AUTOSAR XML (schema 4-0-3)
package /MICROSAR/Dem_swc/DataTypes
  19 x impl type:
    Dem_EventIdType: range raw 1..65535, implementation-data-type=uint16
    Dem_RatioIdType: range raw 1..65535, implementation-data-type=uint16
    Dem_DTCStatusMaskType: range raw 0..255, implementation-data-type=uint8
    Dem_OperationCycleIdType: range raw 0..255, implementation-data-type=uint8
    Dem_DTCGroupType: range raw 0..16777215, implementation-data-type=uint32
    Dem_MaxDataValueType: category=ARRAY, sw-calibration-access=READ-ONLY
      element Dem_MaxDataValueTypeElement: array-size=1, array-size-semantics=FIXED-SIZE, implementation-data-type=uint8
    Dem_EventStatusType: compu {0=DEM_EVENT_STATUS_PASSED, 1=DEM_EVENT_STATUS_FAILED, 2=DEM_EVENT_STATUS_PREPASSED, 3=DEM_EVENT_STATUS_PREFAILED}, implementation-data-type=uint8
    Dem_EventStatusExtendedType: compu {1=DEM_UDS_STATUS_TF, 2=DEM_UDS_STATUS_TFTOC, 4=DEM_UDS_STATUS_PDTC, 8=DEM_UDS_STATUS_CDTC, 16=DEM_UDS_STATUS_TNCSLC, 32=DEM_UDS_STATUS_TFSLC, 64=DEM_UDS_STATUS_TNCTOC, 128=DEM_UDS_STATUS_WIR}, implementation-data-type=uint8
    Dem_InitMonitorReasonType: compu {1=DEM_INIT_MONITOR_CLEAR, 2=DEM_INIT_MONITOR_RESTART, 3=DEM_INIT_MONITOR_REENABLED}, implementation-data-type=uint8
    Dem_DTCOriginType: compu {1=DEM_DTC_ORIGIN_PRIMARY_MEMORY, 2=DEM_DTC_ORIGIN_MIRROR_MEMORY, 3=DEM_DTC_ORIGIN_PERMANENT_MEMORY, 4=DEM_DTC_ORIGIN_SECONDARY_MEMORY}, implementation-data-type=uint8
    Dem_DTCFormatType: compu {0=DEM_DTC_FORMAT_OBD, 1=DEM_DTC_FORMAT_UDS, 2=DEM_DTC_FORMAT_J1939}, implementation-data-type=uint8
    Dem_OperationCycleStateType: compu {0=DEM_CYCLE_STATE_START, 1=DEM_CYCLE_STATE_END}, implementation-data-type=uint8
    Dem_IndicatorStatusType: compu {0=DEM_INDICATOR_OFF, 1=DEM_INDICATOR_CONTINUOUS, 2=DEM_INDICATOR_BLINKING, 3=DEM_INDICATOR_BLINK_CONT, 4=DEM_INDICATOR_SLOW_FLASH, 5=DEM_INDICATOR_FAST_FLASH, 6=DEM_INDICATOR_ON_DEMAND, 7=DEM_INDICATOR_SHORT}, implementation-data-type=uint8
    Dem_DTCKindType: compu {1=DEM_DTC_KIND_ALL_DTCS, 2=DEM_DTC_KIND_EMISSION_REL_DTCS}, implementation-data-type=uint8
    Dem_IumprDenomCondIdType: compu {1=DEM_IUMPR_GENERAL_DENOMINATOR, 2=DEM_IUMPR_DEN_COND_COLDSTART, 3=DEM_IUMPR_DEN_COND_EVAP, 4=DEM_IUMPR_DEN_COND_500MI}, implementation-data-type=uint8
    Dem_IumprDenomCondStatusType: compu {0=DEM_IUMPR_DEN_STATUS_NOT_REACHED, 1=DEM_IUMPR_DEN_STATUS_REACHED, 2=DEM_IUMPR_DEN_STATUS_INHIBITED}, implementation-data-type=uint8
    Dem_DebounceResetStatusType: compu {0=DEM_DEBOUNCE_STATUS_FREEZE, 1=DEM_DEBOUNCE_STATUS_RESET}, implementation-data-type=uint8
    Dem_DebouncingStateType: compu {1=DEM_TEMPORARILY_DEFECTIVE, 2=DEM_FINALLY_DEFECTIVE, 4=DEM_TEMPORARILY_HEALED, 8=DEM_TEST_COMPLETE, 16=DEM_DTR_UPDATE}, implementation-data-type=uint8
    DataArray_Type_1: category=ARRAY, sw-calibration-access=READ-ONLY
      element DataArray_Type_1Element: array-size=1, array-size-semantics=FIXED-SIZE, implementation-data-type=uint8
package /MICROSAR/Dem_swc/Interfaces
  11 x client server interface, all with is-service=true, service-kind=DIAGNOSTIC-EVENT-MANAGER:
    CddIf
      operation ClearDTC: possible-error=[CddIf/DEM_CLEAR_WRONG_DTC, CddIf/DEM_CLEAR_WRONG_DTCORIGIN, CddIf/DEM_CLEAR_FAILED, CddIf/DEM_CLEAR_PENDING, CddIf/DEM_CLEAR_BUSY]
        arg DTC: type=uint32, direction=IN
        arg DTCFormat: type=Dem_DTCFormatType, direction=IN
        arg DTCOrigin: type=Dem_DTCOriginType, direction=IN
      5 x error:
        DEM_CLEAR_WRONG_DTC: error-code=1
        DEM_CLEAR_WRONG_DTCORIGIN: error-code=2
        DEM_CLEAR_FAILED: error-code=3
        DEM_CLEAR_PENDING: error-code=4
        DEM_CLEAR_BUSY: error-code=5
    DemServices
      operation GetPostRunRequested: possible-error=DemServices/E_NOT_OK
        arg IsRequested: type=boolean, direction=OUT
      operation GetDTCStatusAvailabilityMask: possible-error=DemServices/E_NOT_OK
        arg DTCStatusMask: type=uint8, direction=OUT
      error E_NOT_OK: error-code=1
    EvMemOverflowIndication
      operation GetEventMemoryOverflow: possible-error=EvMemOverflowIndication/E_NOT_OK
        arg OverflowIndication: type=boolean, direction=OUT
      operation GetNumberOfEventMemoryEntries: possible-error=EvMemOverflowIndication/E_NOT_OK
        arg NumberOfEventMemoryEntries: type=uint8, direction=OUT
      error E_NOT_OK: error-code=1
    GeneralDiagnosticInfo
      9 x operation:
        GetEventStatus: possible-error=GeneralDiagnosticInfo/E_NOT_OK
          arg EventId: type=Dem_EventIdType, direction=IN
          arg EventStatusExtended: type=Dem_EventStatusExtendedType, direction=OUT
        GetEventFailed: possible-error=GeneralDiagnosticInfo/E_NOT_OK
          arg EventId: type=Dem_EventIdType, direction=IN
          arg EventFailed: type=boolean, direction=OUT
        GetEventTested: possible-error=GeneralDiagnosticInfo/E_NOT_OK
          arg EventId: type=Dem_EventIdType, direction=IN
          arg EventTested: type=boolean, direction=OUT
        GetDTCOfEvent: possible-error=[GeneralDiagnosticInfo/E_NOT_OK, GeneralDiagnosticInfo/DEM_E_NO_DTC_AVAILABLE]
          arg EventId: type=Dem_EventIdType, direction=IN
          arg DTCFormat: type=Dem_DTCFormatType, direction=IN
          arg DTCOfEvent: type=uint32, direction=OUT
        GetFaultDetectionCounter: possible-error=[GeneralDiagnosticInfo/E_NOT_OK, GeneralDiagnosticInfo/DEM_E_NO_FDC_AVAILABLE]
          arg EventId: type=Dem_EventIdType, direction=IN
          arg FaultDetectionCounter: type=sint8, direction=OUT
        GetEventFreezeFrameData: possible-error=[GeneralDiagnosticInfo/E_NOT_OK, GeneralDiagnosticInfo/DEM_E_NODATAAVAILABLE, GeneralDiagnosticInfo/DEM_E_WRONG_RECORDNUMBER, GeneralDiagnosticInfo/DEM_E_WRONG_DIDNUMBER]
          5 x arg:
            EventId: type=Dem_EventIdType, direction=IN
            RecordNumber: type=uint8, direction=IN
            ReportTotalRecord: type=boolean, direction=IN
            DataId: type=uint16, direction=IN
            DestBuffer: type=Dem_MaxDataValueType, direction=OUT
        GetEventExtendedDataRecord: possible-error=[GeneralDiagnosticInfo/E_NOT_OK, GeneralDiagnosticInfo/DEM_E_NODATAAVAILABLE, GeneralDiagnosticInfo/DEM_E_WRONG_RECORDNUMBER]
          arg EventId: type=Dem_EventIdType, direction=IN
          arg RecordNumber: type=uint8, direction=IN
          arg DestBuffer: type=Dem_MaxDataValueType, direction=OUT
        GetEventEnableCondition: possible-error=GeneralDiagnosticInfo/E_NOT_OK
          arg EventId: type=Dem_EventIdType, direction=IN
          arg ConditionFullfilled: type=boolean, direction=OUT
        GetDebouncingOfEvent: possible-error=GeneralDiagnosticInfo/E_NOT_OK
          arg EventId: type=Dem_EventIdType, direction=IN
          arg DebouncingState: type=Dem_DebouncingStateType, direction=OUT
      6 x error:
        E_NOT_OK: error-code=1
        DEM_E_NO_DTC_AVAILABLE: error-code=2
        DEM_E_NO_FDC_AVAILABLE: error-code=3
        DEM_E_NODATAAVAILABLE: error-code=48
        DEM_E_WRONG_RECORDNUMBER: error-code=49
        DEM_E_WRONG_DIDNUMBER: error-code=50
    DiagnosticInfo
      9 x operation:
        GetEventStatus: possible-error=DiagnosticInfo/E_NOT_OK
          arg EventStatusExtended: type=Dem_EventStatusExtendedType, direction=OUT
        GetEventFailed: possible-error=DiagnosticInfo/E_NOT_OK
          arg EventFailed: type=boolean, direction=OUT
        GetEventTested: possible-error=DiagnosticInfo/E_NOT_OK
          arg EventTested: type=boolean, direction=OUT
        GetDTCOfEvent: possible-error=[DiagnosticInfo/E_NOT_OK, DiagnosticInfo/DEM_E_NO_DTC_AVAILABLE]
          arg DTCFormat: type=Dem_DTCFormatType, direction=IN
          arg DTCOfEvent: type=uint32, direction=OUT
        GetFaultDetectionCounter: possible-error=[DiagnosticInfo/E_NOT_OK, DiagnosticInfo/DEM_E_NO_FDC_AVAILABLE]
          arg FaultDetectionCounter: type=sint8, direction=OUT
        GetEventFreezeFrameData: possible-error=[DiagnosticInfo/E_NOT_OK, DiagnosticInfo/DEM_E_NODATAAVAILABLE, DiagnosticInfo/DEM_E_WRONG_RECORDNUMBER, DiagnosticInfo/DEM_E_WRONG_DIDNUMBER]
          4 x arg:
            RecordNumber: type=uint8, direction=IN
            ReportTotalRecord: type=boolean, direction=IN
            DataId: type=uint16, direction=IN
            DestBuffer: type=Dem_MaxDataValueType, direction=OUT
        GetEventExtendedDataRecord: possible-error=[DiagnosticInfo/E_NOT_OK, DiagnosticInfo/DEM_E_NODATAAVAILABLE, DiagnosticInfo/DEM_E_WRONG_RECORDNUMBER]
          arg RecordNumber: type=uint8, direction=IN
          arg DestBuffer: type=Dem_MaxDataValueType, direction=OUT
        GetEventEnableCondition: possible-error=DiagnosticInfo/E_NOT_OK
          arg ConditionFullfilled: type=boolean, direction=OUT
        GetDebouncingOfEvent: possible-error=DiagnosticInfo/E_NOT_OK
          arg DebouncingState: type=Dem_DebouncingStateType, direction=OUT
      6 x error:
        E_NOT_OK: error-code=1
        DEM_E_NO_DTC_AVAILABLE: error-code=2
        DEM_E_NO_FDC_AVAILABLE: error-code=3
        DEM_E_NODATAAVAILABLE: error-code=48
        DEM_E_WRONG_RECORDNUMBER: error-code=49
        DEM_E_WRONG_DIDNUMBER: error-code=50
    DiagnosticMonitor
      10 x operation:
        SetEventStatus: possible-error=DiagnosticMonitor/E_NOT_OK
          arg EventStatus: type=Dem_EventStatusType, direction=IN
        ResetEventStatus: possible-error=DiagnosticMonitor/E_NOT_OK
        ResetEventDebounceStatus: possible-error=DiagnosticMonitor/E_NOT_OK
          arg DebounceResetStatus: type=Dem_DebounceResetStatusType, direction=IN
        GetEventStatus: possible-error=DiagnosticMonitor/E_NOT_OK
          arg EventStatusExtended: type=Dem_EventStatusExtendedType, direction=OUT
        GetEventFailed: possible-error=DiagnosticMonitor/E_NOT_OK
          arg EventFailed: type=boolean, direction=OUT
        GetEventTested: possible-error=DiagnosticMonitor/E_NOT_OK
          arg EventTested: type=boolean, direction=OUT
        GetDTCOfEvent: possible-error=[DiagnosticMonitor/E_NOT_OK, DiagnosticMonitor/DEM_E_NO_DTC_AVAILABLE]
          arg DTCFormat: type=Dem_DTCFormatType, direction=IN
          arg DTCOfEvent: type=uint32, direction=OUT
        GetFaultDetectionCounter: possible-error=[DiagnosticMonitor/E_NOT_OK, DiagnosticMonitor/DEM_E_NO_FDC_AVAILABLE]
          arg FaultDetectionCounter: type=sint8, direction=OUT
        GetEventFreezeFrameData: possible-error=[DiagnosticMonitor/E_NOT_OK, DiagnosticMonitor/DEM_E_NODATAAVAILABLE, DiagnosticMonitor/DEM_E_WRONG_RECORDNUMBER, DiagnosticMonitor/DEM_E_WRONG_DIDNUMBER]
          4 x arg:
            RecordNumber: type=uint8, direction=IN
            ReportTotalRecord: type=boolean, direction=IN
            DataId: type=uint16, direction=IN
            DestBuffer: type=Dem_MaxDataValueType, direction=OUT
        GetEventExtendedDataRecord: possible-error=[DiagnosticMonitor/E_NOT_OK, DiagnosticMonitor/DEM_E_NODATAAVAILABLE, DiagnosticMonitor/DEM_E_WRONG_RECORDNUMBER]
          arg RecordNumber: type=uint8, direction=IN
          arg DestBuffer: type=Dem_MaxDataValueType, direction=OUT
      6 x error:
        E_NOT_OK: error-code=1
        DEM_E_NO_DTC_AVAILABLE: error-code=2
        DEM_E_NO_FDC_AVAILABLE: error-code=3
        DEM_E_NODATAAVAILABLE: error-code=48
        DEM_E_WRONG_RECORDNUMBER: error-code=49
        DEM_E_WRONG_DIDNUMBER: error-code=50
    DcmIf
      5 x operation:
        DcmClearDTC: possible-error=[DcmIf/DEM_CLEAR_WRONG_DTC, DcmIf/DEM_CLEAR_WRONG_DTCORIGIN, DcmIf/DEM_CLEAR_FAILED, DcmIf/DEM_CLEAR_PENDING, DcmIf/DEM_CLEAR_BUSY]
          arg DTC: type=uint32, direction=IN
          arg DTCFormat: type=Dem_DTCFormatType, direction=IN
          arg DTCOrigin: type=Dem_DTCOriginType, direction=IN
        DcmGetNextFilteredDTCAndFDC: possible-error=DEM_FILTERED_NO_MATCHING_DTC
          arg DTC: type=uint32, direction=OUT
          arg DTCFaultDetectionCounter: type=sint8, direction=OUT
        DcmEnableDTCSetting: possible-error=[DEM_CONTROL_DTC_SETTING_N_OK, DEM_CONTROL_DTC_WRONG_DTCGROUP]
          arg DTCGroup: type=Dem_DTCGroupType, direction=IN
          arg DTCKind: type=Dem_DTCKindType, direction=IN
        DcmGetFreezeFrameDataByDTC: possible-error=[DEM_GET_FFDATABYDTC_WRONG_DTC, DEM_GET_FFDATABYDTC_WRONG_DTCORIGIN, DEM_GET_FFDATABYDTC_WRONG_RECORDNUMBER, DEM_GET_FFDATABYDTC_WRONG_BUFFERSIZE, DEM_GET_FFDATABYDTC_PENDING]
          5 x arg:
            DTC: type=uint32, direction=IN
            DTCOrigin: type=Dem_DTCOriginType, direction=IN
            RecordNumber: type=uint8, direction=IN
            DestBuffer: type=uint8, direction=OUT
            BufSize: type=uint16, direction=INOUT
        DcmGetExtendedDataRecordByDTC: possible-error=[DEM_RECORD_WRONG_DTC, DEM_RECORD_WRONG_DTCORIGIN, DEM_RECORD_WRONG_NUMBER, DEM_RECORD_WRONG_BUFFERSIZE, DEM_RECORD_PENDING]
          5 x arg:
            DTC: type=uint32, direction=IN
            DTCOrigin: type=Dem_DTCOriginType, direction=IN
            ExtendedDataNumber: type=uint8, direction=IN
            DestBuffer: type=uint8, direction=OUT
            BufSize: type=uint16, direction=INOUT
      18 x error:
        DEM_CLEAR_WRONG_DTC: error-code=1
        DEM_CONTROL_DTC_SETTING_N_OK: error-code=1
        DEM_FILTERED_NO_MATCHING_DTC: error-code=1
        DEM_GET_FFDATABYDTC_WRONG_DTC: error-code=1
        DEM_RECORD_WRONG_DTC: error-code=1
        DEM_CLEAR_WRONG_DTCORIGIN: error-code=2
        DEM_CONTROL_DTC_WRONG_DTCGROUP: error-code=2
        DEM_GET_FFDATABYDTC_WRONG_DTCORIGIN: error-code=2
        DEM_RECORD_WRONG_DTCORIGIN: error-code=2
        DEM_CLEAR_FAILED: error-code=3
        DEM_GET_FFDATABYDTC_WRONG_RECORDNUMBER: error-code=3
        DEM_RECORD_WRONG_NUMBER: error-code=3
        DEM_CLEAR_PENDING: error-code=4
        DEM_GET_FFDATABYDTC_WRONG_BUFFERSIZE: error-code=4
        DEM_RECORD_WRONG_BUFFERSIZE: error-code=4
        DEM_CLEAR_BUSY: error-code=5
        DEM_GET_FFDATABYDTC_PENDING: error-code=5
        DEM_RECORD_PENDING: error-code=5
    OperationCycle
      operation SetOperationCycleState: possible-error=OperationCycle/E_NOT_OK
        arg CycleState: type=Dem_OperationCycleStateType, direction=IN
      error E_NOT_OK: error-code=1
    CSDataServices_DID_0_Unknown_1
      operation ReadData: possible-error=CSDataServices_DID_0_Unknown_1/E_NOT_OK
        arg Data: type=DataArray_Type_1, direction=OUT
      error E_NOT_OK: error-code=1
    CSDataServices_DID_0x1_Unknown_1
      operation ReadData: possible-error=CSDataServices_DID_0x1_Unknown_1/E_NOT_OK
        arg Data: type=DataArray_Type_1, direction=OUT
      error E_NOT_OK: error-code=1
    CSDataServices_ExtendedDataRecord1_Unknown_1
      operation ReadData: possible-error=CSDataServices_ExtendedDataRecord1_Unknown_1/E_NOT_OK
        arg Data: type=DataArray_Type_1, direction=OUT
      error E_NOT_OK: error-code=1
package /MICROSAR/Dem_swc/ComponentTypes
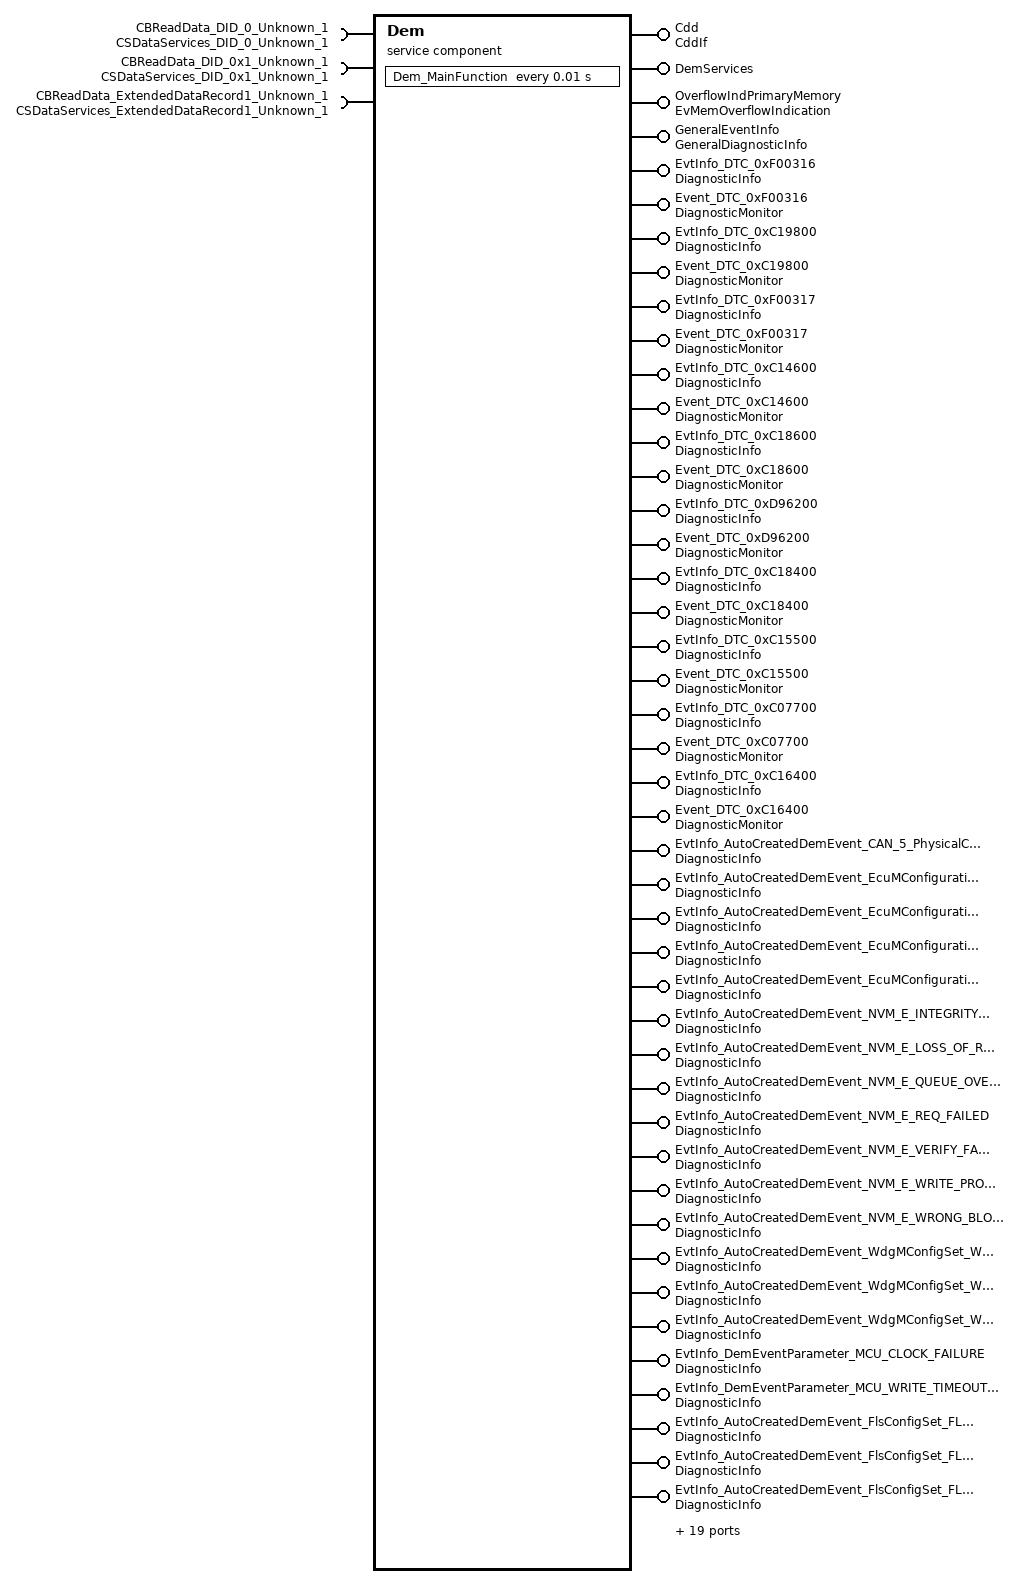
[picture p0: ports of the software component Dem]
  service sw component type Dem: category=SERVICE_COMPONENT
    63 x provide port:
      Cdd: provided-interface=CddIf
      DemServices: provided-interface=DemServices
      OverflowIndPrimaryMemory: provided-interface=EvMemOverflowIndication
      GeneralEventInfo: provided-interface=GeneralDiagnosticInfo
      EvtInfo_DTC_0xF00316: provided-interface=DiagnosticInfo
      Event_DTC_0xF00316: provided-interface=DiagnosticMonitor
      EvtInfo_DTC_0xC19800: provided-interface=DiagnosticInfo
      Event_DTC_0xC19800: provided-interface=DiagnosticMonitor
      EvtInfo_DTC_0xF00317: provided-interface=DiagnosticInfo
      Event_DTC_0xF00317: provided-interface=DiagnosticMonitor
      EvtInfo_DTC_0xC14600: provided-interface=DiagnosticInfo
      Event_DTC_0xC14600: provided-interface=DiagnosticMonitor
      EvtInfo_DTC_0xC18600: provided-interface=DiagnosticInfo
      Event_DTC_0xC18600: provided-interface=DiagnosticMonitor
      EvtInfo_DTC_0xD96200: provided-interface=DiagnosticInfo
      Event_DTC_0xD96200: provided-interface=DiagnosticMonitor
      EvtInfo_DTC_0xC18400: provided-interface=DiagnosticInfo
      Event_DTC_0xC18400: provided-interface=DiagnosticMonitor
      EvtInfo_DTC_0xC15500: provided-interface=DiagnosticInfo
      Event_DTC_0xC15500: provided-interface=DiagnosticMonitor
      EvtInfo_DTC_0xC07700: provided-interface=DiagnosticInfo
      Event_DTC_0xC07700: provided-interface=DiagnosticMonitor
      EvtInfo_DTC_0xC16400: provided-interface=DiagnosticInfo
      Event_DTC_0xC16400: provided-interface=DiagnosticMonitor
      EvtInfo_AutoCreatedDemEvent_CAN_5_PhysicalChannel_09246746_CANSM_E_BUS_OFF: provided-interface=DiagnosticInfo
      EvtInfo_AutoCreatedDemEvent_EcuMConfiguration_ECUM_E_ALL_RUN_REQUESTS_KILLED: provided-interface=DiagnosticInfo
      EvtInfo_AutoCreatedDemEvent_EcuMConfiguration_ECUM_E_CONFIGURATION_DATA_INCONSISTENT: provided-interface=DiagnosticInfo
      EvtInfo_AutoCreatedDemEvent_EcuMConfiguration_ECUM_E_RAM_CHECK_FAILED: provided-interface=DiagnosticInfo
      EvtInfo_AutoCreatedDemEvent_EcuMConfiguration_ECUM_E_IMPROPER_CALLER: provided-interface=DiagnosticInfo
      EvtInfo_AutoCreatedDemEvent_NVM_E_INTEGRITY_FAILED: provided-interface=DiagnosticInfo
      EvtInfo_AutoCreatedDemEvent_NVM_E_LOSS_OF_REDUNDANCY: provided-interface=DiagnosticInfo
      EvtInfo_AutoCreatedDemEvent_NVM_E_QUEUE_OVERFLOW: provided-interface=DiagnosticInfo
      EvtInfo_AutoCreatedDemEvent_NVM_E_REQ_FAILED: provided-interface=DiagnosticInfo
      EvtInfo_AutoCreatedDemEvent_NVM_E_VERIFY_FAILED: provided-interface=DiagnosticInfo
      EvtInfo_AutoCreatedDemEvent_NVM_E_WRITE_PROTECTED: provided-interface=DiagnosticInfo
      EvtInfo_AutoCreatedDemEvent_NVM_E_WRONG_BLOCK_ID: provided-interface=DiagnosticInfo
      EvtInfo_AutoCreatedDemEvent_WdgMConfigSet_WDGM_E_IMPROPER_CALLER: provided-interface=DiagnosticInfo
      EvtInfo_AutoCreatedDemEvent_WdgMConfigSet_WDGM_E_MONITORING: provided-interface=DiagnosticInfo
      EvtInfo_AutoCreatedDemEvent_WdgMConfigSet_WDGM_E_SET_MODE: provided-interface=DiagnosticInfo
      EvtInfo_DemEventParameter_MCU_CLOCK_FAILURE: provided-interface=DiagnosticInfo
      EvtInfo_DemEventParameter_MCU_WRITE_TIMEOUT_FAILURE: provided-interface=DiagnosticInfo
      EvtInfo_AutoCreatedDemEvent_FlsConfigSet_FLS_E_COMPARE_FAILED: provided-interface=DiagnosticInfo
      EvtInfo_AutoCreatedDemEvent_FlsConfigSet_FLS_E_ERASE_FAILED: provided-interface=DiagnosticInfo
      EvtInfo_AutoCreatedDemEvent_FlsConfigSet_FLS_E_READ_FAILED: provided-interface=DiagnosticInfo
      EvtInfo_AutoCreatedDemEvent_FlsConfigSet_FLS_E_UNEXPECTED_FLASH_ID: provided-interface=DiagnosticInfo
      EvtInfo_AutoCreatedDemEvent_FlsConfigSet_FLS_E_WRITE_FAILED: provided-interface=DiagnosticInfo
      EvtInfo_AutoCreatedDemEvent_WDG_E_DISABLE_REJECTED: provided-interface=DiagnosticInfo
      EvtInfo_AutoCreatedDemEvent_WDG_E_MODE_FAILED: provided-interface=DiagnosticInfo
      EvtInfo_AutoCreatedDemEvent_FlsConfigSet_FLS_E_READ_FAILED_DED: provided-interface=DiagnosticInfo
      EvtInfo_DemEventParameter_PORT_WRITE_TIMEOUT_FAILURE: provided-interface=DiagnosticInfo
      EvtInfo_DemEventParameter_WDG_TRIGGER_TIMEOUT: provided-interface=DiagnosticInfo
      EvtInfo_AutoCreatedDemEvent_SpiDriver_SPI_E_HARDWARE_ERROR: provided-interface=DiagnosticInfo
      EvtInfo_AutoCreatedDemEvent_SpiDriver_SPI_E_DATA_TX_TIMEOUT_FAILURE: provided-interface=DiagnosticInfo
      EvtInfo_AutoCreatedDemEvent_CSM_E_INIT_FAILED: provided-interface=DiagnosticInfo
      EvtInfo_RAMTST_E_RAM_FAILURE: provided-interface=DiagnosticInfo
      EvtInfo_AutoCreatedDemEvent_WdgMConfigSet_WDGM_E_IMPROPER_CALLER_1: provided-interface=DiagnosticInfo
      EvtInfo_AutoCreatedDemEvent_WdgMConfigSet_WDGM_E_MONITORING_1: provided-interface=DiagnosticInfo
      EvtInfo_AutoCreatedDemEvent_WdgMConfigSet_WDGM_E_SET_MODE_1: provided-interface=DiagnosticInfo
      EvtInfo_DemEventParameter_GPT_E_TIMEOUT: provided-interface=DiagnosticInfo
      Event_DemEventParameter_GPT_E_TIMEOUT: provided-interface=DiagnosticMonitor
      Dcm: provided-interface=DcmIf
      OpCycle_IgnitionCycle: provided-interface=OperationCycle
      OpCycle_PowerCycle: provided-interface=OperationCycle
    require port CBReadData_DID_0_Unknown_1: required-interface=CSDataServices_DID_0_Unknown_1
    require port CBReadData_DID_0x1_Unknown_1: required-interface=CSDataServices_DID_0x1_Unknown_1
    require port CBReadData_ExtendedDataRecord1_Unknown_1: required-interface=CSDataServices_ExtendedDataRecord1_Unknown_1
    behavior DemInternalBehavior: handle-termination-and-restart=NO-SUPPORT, included-data-type-set=data-type=[Dem_EventIdType, Dem_RatioIdType, Dem_EventStatusType, Dem_EventStatusExtendedType, Dem_DTCFormatType, Dem_InitMonitorReasonType, Dem_OperationCycleStateType, Dem_DTCStatusMaskType, Dem_IndicatorStatusType, Dem_MaxDataValueType, Dem_DTCKindType, Dem_DTCGroupType, Dem_IumprDenomCondIdType, Dem_IumprDenomCondStatusType, Dem_DebounceResetStatusType, Dem_DebouncingStateType]
      timing event Timer_Dem_MainFunction: start-on-event=Dem_MainFunction, period=0.01
      536 x operation invoked event:
        OpEventClearDTC_ClearDTC_Cdd: start-on-event=ClearDTC, operation=Cdd.ClearDTC
        OpEventPostRunRequested_GetPostRunRequested_DemServices: start-on-event=PostRunRequested, operation=DemServices.GetPostRunRequested
        OpEventGetDTCStatusAvailabilityMask_GetDTCStatusAvailabilityMask_DemServices: start-on-event=GetDTCStatusAvailabilityMask, operation=DemServices.GetDTCStatusAvailabilityMask
        OpEventGetEventMemoryOverflow_GetEventMemoryOverflow_OverflowIndPrimaryMemory: start-on-event=GetEventMemoryOverflow, operation=OverflowIndPrimaryMemory.GetEventMemoryOverflow
        OpEventGetNumberOfEventMemoryEntries_GetNumberOfEventMemoryEntries_OverflowIndPrimaryMemory: start-on-event=GetNumberOfEventMemoryEntries, operation=OverflowIndPrimaryMemory.GetNumberOfEventMemoryEntries
        OpEventGetEventStatus_GetEventStatus_GeneralEventInfo: start-on-event=GetEventStatus, operation=GeneralEventInfo.GetEventStatus
        OpEventGetEventStatus_GetEventStatus_EvtInfo_DTC_0xF00316: start-on-event=GetEventStatus, operation=EvtInfo_DTC_0xF00316.GetEventStatus
        OpEventGetEventStatus_GetEventStatus_Event_DTC_0xF00316: start-on-event=GetEventStatus, operation=Event_DTC_0xF00316.GetEventStatus
        OpEventGetEventStatus_GetEventStatus_EvtInfo_DTC_0xC19800: start-on-event=GetEventStatus, operation=EvtInfo_DTC_0xC19800.GetEventStatus
        OpEventGetEventStatus_GetEventStatus_Event_DTC_0xC19800: start-on-event=GetEventStatus, operation=Event_DTC_0xC19800.GetEventStatus
        OpEventGetEventStatus_GetEventStatus_EvtInfo_DTC_0xF00317: start-on-event=GetEventStatus, operation=EvtInfo_DTC_0xF00317.GetEventStatus
        OpEventGetEventStatus_GetEventStatus_Event_DTC_0xF00317: start-on-event=GetEventStatus, operation=Event_DTC_0xF00317.GetEventStatus
        OpEventGetEventStatus_GetEventStatus_EvtInfo_DTC_0xC14600: start-on-event=GetEventStatus, operation=EvtInfo_DTC_0xC14600.GetEventStatus
        OpEventGetEventStatus_GetEventStatus_Event_DTC_0xC14600: start-on-event=GetEventStatus, operation=Event_DTC_0xC14600.GetEventStatus
        OpEventGetEventStatus_GetEventStatus_EvtInfo_DTC_0xC18600: start-on-event=GetEventStatus, operation=EvtInfo_DTC_0xC18600.GetEventStatus
        OpEventGetEventStatus_GetEventStatus_Event_DTC_0xC18600: start-on-event=GetEventStatus, operation=Event_DTC_0xC18600.GetEventStatus
        OpEventGetEventStatus_GetEventStatus_EvtInfo_DTC_0xD96200: start-on-event=GetEventStatus, operation=EvtInfo_DTC_0xD96200.GetEventStatus
        OpEventGetEventStatus_GetEventStatus_Event_DTC_0xD96200: start-on-event=GetEventStatus, operation=Event_DTC_0xD96200.GetEventStatus
        OpEventGetEventStatus_GetEventStatus_EvtInfo_DTC_0xC18400: start-on-event=GetEventStatus, operation=EvtInfo_DTC_0xC18400.GetEventStatus
        OpEventGetEventStatus_GetEventStatus_Event_DTC_0xC18400: start-on-event=GetEventStatus, operation=Event_DTC_0xC18400.GetEventStatus
        OpEventGetEventStatus_GetEventStatus_EvtInfo_DTC_0xC15500: start-on-event=GetEventStatus, operation=EvtInfo_DTC_0xC15500.GetEventStatus
        OpEventGetEventStatus_GetEventStatus_Event_DTC_0xC15500: start-on-event=GetEventStatus, operation=Event_DTC_0xC15500.GetEventStatus
        OpEventGetEventStatus_GetEventStatus_EvtInfo_DTC_0xC07700: start-on-event=GetEventStatus, operation=EvtInfo_DTC_0xC07700.GetEventStatus
        OpEventGetEventStatus_GetEventStatus_Event_DTC_0xC07700: start-on-event=GetEventStatus, operation=Event_DTC_0xC07700.GetEventStatus
        OpEventGetEventStatus_GetEventStatus_EvtInfo_DTC_0xC16400: start-on-event=GetEventStatus, operation=EvtInfo_DTC_0xC16400.GetEventStatus
        OpEventGetEventStatus_GetEventStatus_Event_DTC_0xC16400: start-on-event=GetEventStatus, operation=Event_DTC_0xC16400.GetEventStatus
        OpEventGetEventStatus_GetEventStatus_EvtInfo_AutoCreatedDemEvent_CAN_5_PhysicalChannel_09246746_CANSM_E_BUS_OFF: start-on-event=GetEventStatus, operation=EvtInfo_AutoCreatedDemEvent_CAN_5_PhysicalChannel_09246746_CANSM_E_BUS_OFF.GetEventStatus
        OpEventGetEventStatus_GetEventStatus_EvtInfo_AutoCreatedDemEvent_EcuMConfiguration_ECUM_E_ALL_RUN_REQUESTS_KILLED: start-on-event=GetEventStatus, operation=EvtInfo_AutoCreatedDemEvent_EcuMConfiguration_ECUM_E_ALL_RUN_REQUESTS_KILLED.GetEventStatus
        OpEventGetEventStatus_GetEventStatus_EvtInfo_AutoCreatedDemEvent_EcuMConfiguration_ECUM_E_CONFIGURATION_DATA_INCONSISTENT: start-on-event=GetEventStatus, operation=EvtInfo_AutoCreatedDemEvent_EcuMConfiguration_ECUM_E_CONFIGURATION_DATA_INCONSISTENT.GetEventStatus
        OpEventGetEventStatus_GetEventStatus_EvtInfo_AutoCreatedDemEvent_EcuMConfiguration_ECUM_E_RAM_CHECK_FAILED: start-on-event=GetEventStatus, operation=EvtInfo_AutoCreatedDemEvent_EcuMConfiguration_ECUM_E_RAM_CHECK_FAILED.GetEventStatus
        OpEventGetEventStatus_GetEventStatus_EvtInfo_AutoCreatedDemEvent_EcuMConfiguration_ECUM_E_IMPROPER_CALLER: start-on-event=GetEventStatus, operation=EvtInfo_AutoCreatedDemEvent_EcuMConfiguration_ECUM_E_IMPROPER_CALLER.GetEventStatus
        OpEventGetEventStatus_GetEventStatus_EvtInfo_AutoCreatedDemEvent_NVM_E_INTEGRITY_FAILED: start-on-event=GetEventStatus, operation=EvtInfo_AutoCreatedDemEvent_NVM_E_INTEGRITY_FAILED.GetEventStatus
        OpEventGetEventStatus_GetEventStatus_EvtInfo_AutoCreatedDemEvent_NVM_E_LOSS_OF_REDUNDANCY: start-on-event=GetEventStatus, operation=EvtInfo_AutoCreatedDemEvent_NVM_E_LOSS_OF_REDUNDANCY.GetEventStatus
        OpEventGetEventStatus_GetEventStatus_EvtInfo_AutoCreatedDemEvent_NVM_E_QUEUE_OVERFLOW: start-on-event=GetEventStatus, operation=EvtInfo_AutoCreatedDemEvent_NVM_E_QUEUE_OVERFLOW.GetEventStatus
        OpEventGetEventStatus_GetEventStatus_EvtInfo_AutoCreatedDemEvent_NVM_E_REQ_FAILED: start-on-event=GetEventStatus, operation=EvtInfo_AutoCreatedDemEvent_NVM_E_REQ_FAILED.GetEventStatus
        OpEventGetEventStatus_GetEventStatus_EvtInfo_AutoCreatedDemEvent_NVM_E_VERIFY_FAILED: start-on-event=GetEventStatus, operation=EvtInfo_AutoCreatedDemEvent_NVM_E_VERIFY_FAILED.GetEventStatus
        OpEventGetEventStatus_GetEventStatus_EvtInfo_AutoCreatedDemEvent_NVM_E_WRITE_PROTECTED: start-on-event=GetEventStatus, operation=EvtInfo_AutoCreatedDemEvent_NVM_E_WRITE_PROTECTED.GetEventStatus
        OpEventGetEventStatus_GetEventStatus_EvtInfo_AutoCreatedDemEvent_NVM_E_WRONG_BLOCK_ID: start-on-event=GetEventStatus, operation=EvtInfo_AutoCreatedDemEvent_NVM_E_WRONG_BLOCK_ID.GetEventStatus
        OpEventGetEventStatus_GetEventStatus_EvtInfo_AutoCreatedDemEvent_WdgMConfigSet_WDGM_E_IMPROPER_CALLER: start-on-event=GetEventStatus, operation=EvtInfo_AutoCreatedDemEvent_WdgMConfigSet_WDGM_E_IMPROPER_CALLER.GetEventStatus
        OpEventGetEventStatus_GetEventStatus_EvtInfo_AutoCreatedDemEvent_WdgMConfigSet_WDGM_E_MONITORING: start-on-event=GetEventStatus, operation=EvtInfo_AutoCreatedDemEvent_WdgMConfigSet_WDGM_E_MONITORING.GetEventStatus
        OpEventGetEventStatus_GetEventStatus_EvtInfo_AutoCreatedDemEvent_WdgMConfigSet_WDGM_E_SET_MODE: start-on-event=GetEventStatus, operation=EvtInfo_AutoCreatedDemEvent_WdgMConfigSet_WDGM_E_SET_MODE.GetEventStatus
        OpEventGetEventStatus_GetEventStatus_EvtInfo_DemEventParameter_MCU_CLOCK_FAILURE: start-on-event=GetEventStatus, operation=EvtInfo_DemEventParameter_MCU_CLOCK_FAILURE.GetEventStatus
        OpEventGetEventStatus_GetEventStatus_EvtInfo_DemEventParameter_MCU_WRITE_TIMEOUT_FAILURE: start-on-event=GetEventStatus, operation=EvtInfo_DemEventParameter_MCU_WRITE_TIMEOUT_FAILURE.GetEventStatus
        OpEventGetEventStatus_GetEventStatus_EvtInfo_AutoCreatedDemEvent_FlsConfigSet_FLS_E_COMPARE_FAILED: start-on-event=GetEventStatus, operation=EvtInfo_AutoCreatedDemEvent_FlsConfigSet_FLS_E_COMPARE_FAILED.GetEventStatus
        OpEventGetEventStatus_GetEventStatus_EvtInfo_AutoCreatedDemEvent_FlsConfigSet_FLS_E_ERASE_FAILED: start-on-event=GetEventStatus, operation=EvtInfo_AutoCreatedDemEvent_FlsConfigSet_FLS_E_ERASE_FAILED.GetEventStatus
        OpEventGetEventStatus_GetEventStatus_EvtInfo_AutoCreatedDemEvent_FlsConfigSet_FLS_E_READ_FAILED: start-on-event=GetEventStatus, operation=EvtInfo_AutoCreatedDemEvent_FlsConfigSet_FLS_E_READ_FAILED.GetEventStatus
        OpEventGetEventStatus_GetEventStatus_EvtInfo_AutoCreatedDemEvent_FlsConfigSet_FLS_E_UNEXPECTED_FLASH_ID: start-on-event=GetEventStatus, operation=EvtInfo_AutoCreatedDemEvent_FlsConfigSet_FLS_E_UNEXPECTED_FLASH_ID.GetEventStatus
        OpEventGetEventStatus_GetEventStatus_EvtInfo_AutoCreatedDemEvent_FlsConfigSet_FLS_E_WRITE_FAILED: start-on-event=GetEventStatus, operation=EvtInfo_AutoCreatedDemEvent_FlsConfigSet_FLS_E_WRITE_FAILED.GetEventStatus
        OpEventGetEventStatus_GetEventStatus_EvtInfo_AutoCreatedDemEvent_WDG_E_DISABLE_REJECTED: start-on-event=GetEventStatus, operation=EvtInfo_AutoCreatedDemEvent_WDG_E_DISABLE_REJECTED.GetEventStatus
        OpEventGetEventStatus_GetEventStatus_EvtInfo_AutoCreatedDemEvent_WDG_E_MODE_FAILED: start-on-event=GetEventStatus, operation=EvtInfo_AutoCreatedDemEvent_WDG_E_MODE_FAILED.GetEventStatus
        OpEventGetEventStatus_GetEventStatus_EvtInfo_AutoCreatedDemEvent_FlsConfigSet_FLS_E_READ_FAILED_DED: start-on-event=GetEventStatus, operation=EvtInfo_AutoCreatedDemEvent_FlsConfigSet_FLS_E_READ_FAILED_DED.GetEventStatus
        OpEventGetEventStatus_GetEventStatus_EvtInfo_DemEventParameter_PORT_WRITE_TIMEOUT_FAILURE: start-on-event=GetEventStatus, operation=EvtInfo_DemEventParameter_PORT_WRITE_TIMEOUT_FAILURE.GetEventStatus
        OpEventGetEventStatus_GetEventStatus_EvtInfo_DemEventParameter_WDG_TRIGGER_TIMEOUT: start-on-event=GetEventStatus, operation=EvtInfo_DemEventParameter_WDG_TRIGGER_TIMEOUT.GetEventStatus
        OpEventGetEventStatus_GetEventStatus_EvtInfo_AutoCreatedDemEvent_SpiDriver_SPI_E_HARDWARE_ERROR: start-on-event=GetEventStatus, operation=EvtInfo_AutoCreatedDemEvent_SpiDriver_SPI_E_HARDWARE_ERROR.GetEventStatus
        OpEventGetEventStatus_GetEventStatus_EvtInfo_AutoCreatedDemEvent_SpiDriver_SPI_E_DATA_TX_TIMEOUT_FAILURE: start-on-event=GetEventStatus, operation=EvtInfo_AutoCreatedDemEvent_SpiDriver_SPI_E_DATA_TX_TIMEOUT_FAILURE.GetEventStatus
        OpEventGetEventStatus_GetEventStatus_EvtInfo_AutoCreatedDemEvent_CSM_E_INIT_FAILED: start-on-event=GetEventStatus, operation=EvtInfo_AutoCreatedDemEvent_CSM_E_INIT_FAILED.GetEventStatus
        OpEventGetEventStatus_GetEventStatus_EvtInfo_RAMTST_E_RAM_FAILURE: start-on-event=GetEventStatus, operation=EvtInfo_RAMTST_E_RAM_FAILURE.GetEventStatus
        OpEventGetEventStatus_GetEventStatus_EvtInfo_AutoCreatedDemEvent_WdgMConfigSet_WDGM_E_IMPROPER_CALLER_1: start-on-event=GetEventStatus, operation=EvtInfo_AutoCreatedDemEvent_WdgMConfigSet_WDGM_E_IMPROPER_CALLER_1.GetEventStatus
        OpEventGetEventStatus_GetEventStatus_EvtInfo_AutoCreatedDemEvent_WdgMConfigSet_WDGM_E_MONITORING_1: start-on-event=GetEventStatus, operation=EvtInfo_AutoCreatedDemEvent_WdgMConfigSet_WDGM_E_MONITORING_1.GetEventStatus
        OpEventGetEventStatus_GetEventStatus_EvtInfo_AutoCreatedDemEvent_WdgMConfigSet_WDGM_E_SET_MODE_1: start-on-event=GetEventStatus, operation=EvtInfo_AutoCreatedDemEvent_WdgMConfigSet_WDGM_E_SET_MODE_1.GetEventStatus
        OpEventGetEventStatus_GetEventStatus_EvtInfo_DemEventParameter_GPT_E_TIMEOUT: start-on-event=GetEventStatus, operation=EvtInfo_DemEventParameter_GPT_E_TIMEOUT.GetEventStatus
        OpEventGetEventStatus_GetEventStatus_Event_DemEventParameter_GPT_E_TIMEOUT: start-on-event=GetEventStatus, operation=Event_DemEventParameter_GPT_E_TIMEOUT.GetEventStatus
        OpEventGetEventFailed_GetEventFailed_GeneralEventInfo: start-on-event=GetEventFailed, operation=GeneralEventInfo.GetEventFailed
        OpEventGetEventFailed_GetEventFailed_EvtInfo_DTC_0xF00316: start-on-event=GetEventFailed, operation=EvtInfo_DTC_0xF00316.GetEventFailed
        OpEventGetEventFailed_GetEventFailed_Event_DTC_0xF00316: start-on-event=GetEventFailed, operation=Event_DTC_0xF00316.GetEventFailed
        OpEventGetEventFailed_GetEventFailed_EvtInfo_DTC_0xC19800: start-on-event=GetEventFailed, operation=EvtInfo_DTC_0xC19800.GetEventFailed
        OpEventGetEventFailed_GetEventFailed_Event_DTC_0xC19800: start-on-event=GetEventFailed, operation=Event_DTC_0xC19800.GetEventFailed
        OpEventGetEventFailed_GetEventFailed_EvtInfo_DTC_0xF00317: start-on-event=GetEventFailed, operation=EvtInfo_DTC_0xF00317.GetEventFailed
        OpEventGetEventFailed_GetEventFailed_Event_DTC_0xF00317: start-on-event=GetEventFailed, operation=Event_DTC_0xF00317.GetEventFailed
        OpEventGetEventFailed_GetEventFailed_EvtInfo_DTC_0xC14600: start-on-event=GetEventFailed, operation=EvtInfo_DTC_0xC14600.GetEventFailed
        OpEventGetEventFailed_GetEventFailed_Event_DTC_0xC14600: start-on-event=GetEventFailed, operation=Event_DTC_0xC14600.GetEventFailed
        OpEventGetEventFailed_GetEventFailed_EvtInfo_DTC_0xC18600: start-on-event=GetEventFailed, operation=EvtInfo_DTC_0xC18600.GetEventFailed
        OpEventGetEventFailed_GetEventFailed_Event_DTC_0xC18600: start-on-event=GetEventFailed, operation=Event_DTC_0xC18600.GetEventFailed
        OpEventGetEventFailed_GetEventFailed_EvtInfo_DTC_0xD96200: start-on-event=GetEventFailed, operation=EvtInfo_DTC_0xD96200.GetEventFailed
        OpEventGetEventFailed_GetEventFailed_Event_DTC_0xD96200: start-on-event=GetEventFailed, operation=Event_DTC_0xD96200.GetEventFailed
        OpEventGetEventFailed_GetEventFailed_EvtInfo_DTC_0xC18400: start-on-event=GetEventFailed, operation=EvtInfo_DTC_0xC18400.GetEventFailed
        OpEventGetEventFailed_GetEventFailed_Event_DTC_0xC18400: start-on-event=GetEventFailed, operation=Event_DTC_0xC18400.GetEventFailed
        OpEventGetEventFailed_GetEventFailed_EvtInfo_DTC_0xC15500: start-on-event=GetEventFailed, operation=EvtInfo_DTC_0xC15500.GetEventFailed
        OpEventGetEventFailed_GetEventFailed_Event_DTC_0xC15500: start-on-event=GetEventFailed, operation=Event_DTC_0xC15500.GetEventFailed
        OpEventGetEventFailed_GetEventFailed_EvtInfo_DTC_0xC07700: start-on-event=GetEventFailed, operation=EvtInfo_DTC_0xC07700.GetEventFailed
        OpEventGetEventFailed_GetEventFailed_Event_DTC_0xC07700: start-on-event=GetEventFailed, operation=Event_DTC_0xC07700.GetEventFailed
        OpEventGetEventFailed_GetEventFailed_EvtInfo_DTC_0xC16400: start-on-event=GetEventFailed, operation=EvtInfo_DTC_0xC16400.GetEventFailed
        OpEventGetEventFailed_GetEventFailed_Event_DTC_0xC16400: start-on-event=GetEventFailed, operation=Event_DTC_0xC16400.GetEventFailed
        OpEventGetEventFailed_GetEventFailed_EvtInfo_AutoCreatedDemEvent_CAN_5_PhysicalChannel_09246746_CANSM_E_BUS_OFF: start-on-event=GetEventFailed, operation=EvtInfo_AutoCreatedDemEvent_CAN_5_PhysicalChannel_09246746_CANSM_E_BUS_OFF.GetEventFailed
        OpEventGetEventFailed_GetEventFailed_EvtInfo_AutoCreatedDemEvent_EcuMConfiguration_ECUM_E_ALL_RUN_REQUESTS_KILLED: start-on-event=GetEventFailed, operation=EvtInfo_AutoCreatedDemEvent_EcuMConfiguration_ECUM_E_ALL_RUN_REQUESTS_KILLED.GetEventFailed
        OpEventGetEventFailed_GetEventFailed_EvtInfo_AutoCreatedDemEvent_EcuMConfiguration_ECUM_E_CONFIGURATION_DATA_INCONSISTENT: start-on-event=GetEventFailed, operation=EvtInfo_AutoCreatedDemEvent_EcuMConfiguration_ECUM_E_CONFIGURATION_DATA_INCONSISTENT.GetEventFailed
        OpEventGetEventFailed_GetEventFailed_EvtInfo_AutoCreatedDemEvent_EcuMConfiguration_ECUM_E_RAM_CHECK_FAILED: start-on-event=GetEventFailed, operation=EvtInfo_AutoCreatedDemEvent_EcuMConfiguration_ECUM_E_RAM_CHECK_FAILED.GetEventFailed
        OpEventGetEventFailed_GetEventFailed_EvtInfo_AutoCreatedDemEvent_EcuMConfiguration_ECUM_E_IMPROPER_CALLER: start-on-event=GetEventFailed, operation=EvtInfo_AutoCreatedDemEvent_EcuMConfiguration_ECUM_E_IMPROPER_CALLER.GetEventFailed
        OpEventGetEventFailed_GetEventFailed_EvtInfo_AutoCreatedDemEvent_NVM_E_INTEGRITY_FAILED: start-on-event=GetEventFailed, operation=EvtInfo_AutoCreatedDemEvent_NVM_E_INTEGRITY_FAILED.GetEventFailed
        OpEventGetEventFailed_GetEventFailed_EvtInfo_AutoCreatedDemEvent_NVM_E_LOSS_OF_REDUNDANCY: start-on-event=GetEventFailed, operation=EvtInfo_AutoCreatedDemEvent_NVM_E_LOSS_OF_REDUNDANCY.GetEventFailed
        OpEventGetEventFailed_GetEventFailed_EvtInfo_AutoCreatedDemEvent_NVM_E_QUEUE_OVERFLOW: start-on-event=GetEventFailed, operation=EvtInfo_AutoCreatedDemEvent_NVM_E_QUEUE_OVERFLOW.GetEventFailed
        OpEventGetEventFailed_GetEventFailed_EvtInfo_AutoCreatedDemEvent_NVM_E_REQ_FAILED: start-on-event=GetEventFailed, operation=EvtInfo_AutoCreatedDemEvent_NVM_E_REQ_FAILED.GetEventFailed
        OpEventGetEventFailed_GetEventFailed_EvtInfo_AutoCreatedDemEvent_NVM_E_VERIFY_FAILED: start-on-event=GetEventFailed, operation=EvtInfo_AutoCreatedDemEvent_NVM_E_VERIFY_FAILED.GetEventFailed
        OpEventGetEventFailed_GetEventFailed_EvtInfo_AutoCreatedDemEvent_NVM_E_WRITE_PROTECTED: start-on-event=GetEventFailed, operation=EvtInfo_AutoCreatedDemEvent_NVM_E_WRITE_PROTECTED.GetEventFailed
        OpEventGetEventFailed_GetEventFailed_EvtInfo_AutoCreatedDemEvent_NVM_E_WRONG_BLOCK_ID: start-on-event=GetEventFailed, operation=EvtInfo_AutoCreatedDemEvent_NVM_E_WRONG_BLOCK_ID.GetEventFailed
        OpEventGetEventFailed_GetEventFailed_EvtInfo_AutoCreatedDemEvent_WdgMConfigSet_WDGM_E_IMPROPER_CALLER: start-on-event=GetEventFailed, operation=EvtInfo_AutoCreatedDemEvent_WdgMConfigSet_WDGM_E_IMPROPER_CALLER.GetEventFailed
        OpEventGetEventFailed_GetEventFailed_EvtInfo_AutoCreatedDemEvent_WdgMConfigSet_WDGM_E_MONITORING: start-on-event=GetEventFailed, operation=EvtInfo_AutoCreatedDemEvent_WdgMConfigSet_WDGM_E_MONITORING.GetEventFailed
        OpEventGetEventFailed_GetEventFailed_EvtInfo_AutoCreatedDemEvent_WdgMConfigSet_WDGM_E_SET_MODE: start-on-event=GetEventFailed, operation=EvtInfo_AutoCreatedDemEvent_WdgMConfigSet_WDGM_E_SET_MODE.GetEventFailed
        OpEventGetEventFailed_GetEventFailed_EvtInfo_DemEventParameter_MCU_CLOCK_FAILURE: start-on-event=GetEventFailed, operation=EvtInfo_DemEventParameter_MCU_CLOCK_FAILURE.GetEventFailed
        OpEventGetEventFailed_GetEventFailed_EvtInfo_DemEventParameter_MCU_WRITE_TIMEOUT_FAILURE: start-on-event=GetEventFailed, operation=EvtInfo_DemEventParameter_MCU_WRITE_TIMEOUT_FAILURE.GetEventFailed
        OpEventGetEventFailed_GetEventFailed_EvtInfo_AutoCreatedDemEvent_FlsConfigSet_FLS_E_COMPARE_FAILED: start-on-event=GetEventFailed, operation=EvtInfo_AutoCreatedDemEvent_FlsConfigSet_FLS_E_COMPARE_FAILED.GetEventFailed
        OpEventGetEventFailed_GetEventFailed_EvtInfo_AutoCreatedDemEvent_FlsConfigSet_FLS_E_ERASE_FAILED: start-on-event=GetEventFailed, operation=EvtInfo_AutoCreatedDemEvent_FlsConfigSet_FLS_E_ERASE_FAILED.GetEventFailed
        OpEventGetEventFailed_GetEventFailed_EvtInfo_AutoCreatedDemEvent_FlsConfigSet_FLS_E_READ_FAILED: start-on-event=GetEventFailed, operation=EvtInfo_AutoCreatedDemEvent_FlsConfigSet_FLS_E_READ_FAILED.GetEventFailed
        OpEventGetEventFailed_GetEventFailed_EvtInfo_AutoCreatedDemEvent_FlsConfigSet_FLS_E_UNEXPECTED_FLASH_ID: start-on-event=GetEventFailed, operation=EvtInfo_AutoCreatedDemEvent_FlsConfigSet_FLS_E_UNEXPECTED_FLASH_ID.GetEventFailed
        OpEventGetEventFailed_GetEventFailed_EvtInfo_AutoCreatedDemEvent_FlsConfigSet_FLS_E_WRITE_FAILED: start-on-event=GetEventFailed, operation=EvtInfo_AutoCreatedDemEvent_FlsConfigSet_FLS_E_WRITE_FAILED.GetEventFailed
        OpEventGetEventFailed_GetEventFailed_EvtInfo_AutoCreatedDemEvent_WDG_E_DISABLE_REJECTED: start-on-event=GetEventFailed, operation=EvtInfo_AutoCreatedDemEvent_WDG_E_DISABLE_REJECTED.GetEventFailed
        OpEventGetEventFailed_GetEventFailed_EvtInfo_AutoCreatedDemEvent_WDG_E_MODE_FAILED: start-on-event=GetEventFailed, operation=EvtInfo_AutoCreatedDemEvent_WDG_E_MODE_FAILED.GetEventFailed
        OpEventGetEventFailed_GetEventFailed_EvtInfo_AutoCreatedDemEvent_FlsConfigSet_FLS_E_READ_FAILED_DED: start-on-event=GetEventFailed, operation=EvtInfo_AutoCreatedDemEvent_FlsConfigSet_FLS_E_READ_FAILED_DED.GetEventFailed
        OpEventGetEventFailed_GetEventFailed_EvtInfo_DemEventParameter_PORT_WRITE_TIMEOUT_FAILURE: start-on-event=GetEventFailed, operation=EvtInfo_DemEventParameter_PORT_WRITE_TIMEOUT_FAILURE.GetEventFailed
        OpEventGetEventFailed_GetEventFailed_EvtInfo_DemEventParameter_WDG_TRIGGER_TIMEOUT: start-on-event=GetEventFailed, operation=EvtInfo_DemEventParameter_WDG_TRIGGER_TIMEOUT.GetEventFailed
        OpEventGetEventFailed_GetEventFailed_EvtInfo_AutoCreatedDemEvent_SpiDriver_SPI_E_HARDWARE_ERROR: start-on-event=GetEventFailed, operation=EvtInfo_AutoCreatedDemEvent_SpiDriver_SPI_E_HARDWARE_ERROR.GetEventFailed
        OpEventGetEventFailed_GetEventFailed_EvtInfo_AutoCreatedDemEvent_SpiDriver_SPI_E_DATA_TX_TIMEOUT_FAILURE: start-on-event=GetEventFailed, operation=EvtInfo_AutoCreatedDemEvent_SpiDriver_SPI_E_DATA_TX_TIMEOUT_FAILURE.GetEventFailed
        OpEventGetEventFailed_GetEventFailed_EvtInfo_AutoCreatedDemEvent_CSM_E_INIT_FAILED: start-on-event=GetEventFailed, operation=EvtInfo_AutoCreatedDemEvent_CSM_E_INIT_FAILED.GetEventFailed
        OpEventGetEventFailed_GetEventFailed_EvtInfo_RAMTST_E_RAM_FAILURE: start-on-event=GetEventFailed, operation=EvtInfo_RAMTST_E_RAM_FAILURE.GetEventFailed
        OpEventGetEventFailed_GetEventFailed_EvtInfo_AutoCreatedDemEvent_WdgMConfigSet_WDGM_E_IMPROPER_CALLER_1: start-on-event=GetEventFailed, operation=EvtInfo_AutoCreatedDemEvent_WdgMConfigSet_WDGM_E_IMPROPER_CALLER_1.GetEventFailed
        OpEventGetEventFailed_GetEventFailed_EvtInfo_AutoCreatedDemEvent_WdgMConfigSet_WDGM_E_MONITORING_1: start-on-event=GetEventFailed, operation=EvtInfo_AutoCreatedDemEvent_WdgMConfigSet_WDGM_E_MONITORING_1.GetEventFailed
        OpEventGetEventFailed_GetEventFailed_EvtInfo_AutoCreatedDemEvent_WdgMConfigSet_WDGM_E_SET_MODE_1: start-on-event=GetEventFailed, operation=EvtInfo_AutoCreatedDemEvent_WdgMConfigSet_WDGM_E_SET_MODE_1.GetEventFailed
        OpEventGetEventFailed_GetEventFailed_EvtInfo_DemEventParameter_GPT_E_TIMEOUT: start-on-event=GetEventFailed, operation=EvtInfo_DemEventParameter_GPT_E_TIMEOUT.GetEventFailed
        OpEventGetEventFailed_GetEventFailed_Event_DemEventParameter_GPT_E_TIMEOUT: start-on-event=GetEventFailed, operation=Event_DemEventParameter_GPT_E_TIMEOUT.GetEventFailed
        OpEventGetEventTested_GetEventTested_GeneralEventInfo: start-on-event=GetEventTested, operation=GeneralEventInfo.GetEventTested
        OpEventGetEventTested_GetEventTested_EvtInfo_DTC_0xF00316: start-on-event=GetEventTested, operation=EvtInfo_DTC_0xF00316.GetEventTested
        OpEventGetEventTested_GetEventTested_Event_DTC_0xF00316: start-on-event=GetEventTested, operation=Event_DTC_0xF00316.GetEventTested
        OpEventGetEventTested_GetEventTested_EvtInfo_DTC_0xC19800: start-on-event=GetEventTested, operation=EvtInfo_DTC_0xC19800.GetEventTested
        OpEventGetEventTested_GetEventTested_Event_DTC_0xC19800: start-on-event=GetEventTested, operation=Event_DTC_0xC19800.GetEventTested
        OpEventGetEventTested_GetEventTested_EvtInfo_DTC_0xF00317: start-on-event=GetEventTested, operation=EvtInfo_DTC_0xF00317.GetEventTested
        OpEventGetEventTested_GetEventTested_Event_DTC_0xF00317: start-on-event=GetEventTested, operation=Event_DTC_0xF00317.GetEventTested
        OpEventGetEventTested_GetEventTested_EvtInfo_DTC_0xC14600: start-on-event=GetEventTested, operation=EvtInfo_DTC_0xC14600.GetEventTested
        OpEventGetEventTested_GetEventTested_Event_DTC_0xC14600: start-on-event=GetEventTested, operation=Event_DTC_0xC14600.GetEventTested
        OpEventGetEventTested_GetEventTested_EvtInfo_DTC_0xC18600: start-on-event=GetEventTested, operation=EvtInfo_DTC_0xC18600.GetEventTested
        OpEventGetEventTested_GetEventTested_Event_DTC_0xC18600: start-on-event=GetEventTested, operation=Event_DTC_0xC18600.GetEventTested
        OpEventGetEventTested_GetEventTested_EvtInfo_DTC_0xD96200: start-on-event=GetEventTested, operation=EvtInfo_DTC_0xD96200.GetEventTested
        OpEventGetEventTested_GetEventTested_Event_DTC_0xD96200: start-on-event=GetEventTested, operation=Event_DTC_0xD96200.GetEventTested
        OpEventGetEventTested_GetEventTested_EvtInfo_DTC_0xC18400: start-on-event=GetEventTested, operation=EvtInfo_DTC_0xC18400.GetEventTested
        OpEventGetEventTested_GetEventTested_Event_DTC_0xC18400: start-on-event=GetEventTested, operation=Event_DTC_0xC18400.GetEventTested
        OpEventGetEventTested_GetEventTested_EvtInfo_DTC_0xC15500: start-on-event=GetEventTested, operation=EvtInfo_DTC_0xC15500.GetEventTested
        OpEventGetEventTested_GetEventTested_Event_DTC_0xC15500: start-on-event=GetEventTested, operation=Event_DTC_0xC15500.GetEventTested
        OpEventGetEventTested_GetEventTested_EvtInfo_DTC_0xC07700: start-on-event=GetEventTested, operation=EvtInfo_DTC_0xC07700.GetEventTested
        OpEventGetEventTested_GetEventTested_Event_DTC_0xC07700: start-on-event=GetEventTested, operation=Event_DTC_0xC07700.GetEventTested
        OpEventGetEventTested_GetEventTested_EvtInfo_DTC_0xC16400: start-on-event=GetEventTested, operation=EvtInfo_DTC_0xC16400.GetEventTested
        OpEventGetEventTested_GetEventTested_Event_DTC_0xC16400: start-on-event=GetEventTested, operation=Event_DTC_0xC16400.GetEventTested
        OpEventGetEventTested_GetEventTested_EvtInfo_AutoCreatedDemEvent_CAN_5_PhysicalChannel_09246746_CANSM_E_BUS_OFF: start-on-event=GetEventTested, operation=EvtInfo_AutoCreatedDemEvent_CAN_5_PhysicalChannel_09246746_CANSM_E_BUS_OFF.GetEventTested
        OpEventGetEventTested_GetEventTested_EvtInfo_AutoCreatedDemEvent_EcuMConfiguration_ECUM_E_ALL_RUN_REQUESTS_KILLED: start-on-event=GetEventTested, operation=EvtInfo_AutoCreatedDemEvent_EcuMConfiguration_ECUM_E_ALL_RUN_REQUESTS_KILLED.GetEventTested
        OpEventGetEventTested_GetEventTested_EvtInfo_AutoCreatedDemEvent_EcuMConfiguration_ECUM_E_CONFIGURATION_DATA_INCONSISTENT: start-on-event=GetEventTested, operation=EvtInfo_AutoCreatedDemEvent_EcuMConfiguration_ECUM_E_CONFIGURATION_DATA_INCONSISTENT.GetEventTested
        OpEventGetEventTested_GetEventTested_EvtInfo_AutoCreatedDemEvent_EcuMConfiguration_ECUM_E_RAM_CHECK_FAILED: start-on-event=GetEventTested, operation=EvtInfo_AutoCreatedDemEvent_EcuMConfiguration_ECUM_E_RAM_CHECK_FAILED.GetEventTested
        OpEventGetEventTested_GetEventTested_EvtInfo_AutoCreatedDemEvent_EcuMConfiguration_ECUM_E_IMPROPER_CALLER: start-on-event=GetEventTested, operation=EvtInfo_AutoCreatedDemEvent_EcuMConfiguration_ECUM_E_IMPROPER_CALLER.GetEventTested
        OpEventGetEventTested_GetEventTested_EvtInfo_AutoCreatedDemEvent_NVM_E_INTEGRITY_FAILED: start-on-event=GetEventTested, operation=EvtInfo_AutoCreatedDemEvent_NVM_E_INTEGRITY_FAILED.GetEventTested
        OpEventGetEventTested_GetEventTested_EvtInfo_AutoCreatedDemEvent_NVM_E_LOSS_OF_REDUNDANCY: start-on-event=GetEventTested, operation=EvtInfo_AutoCreatedDemEvent_NVM_E_LOSS_OF_REDUNDANCY.GetEventTested
        OpEventGetEventTested_GetEventTested_EvtInfo_AutoCreatedDemEvent_NVM_E_QUEUE_OVERFLOW: start-on-event=GetEventTested, operation=EvtInfo_AutoCreatedDemEvent_NVM_E_QUEUE_OVERFLOW.GetEventTested
        OpEventGetEventTested_GetEventTested_EvtInfo_AutoCreatedDemEvent_NVM_E_REQ_FAILED: start-on-event=GetEventTested, operation=EvtInfo_AutoCreatedDemEvent_NVM_E_REQ_FAILED.GetEventTested
        OpEventGetEventTested_GetEventTested_EvtInfo_AutoCreatedDemEvent_NVM_E_VERIFY_FAILED: start-on-event=GetEventTested, operation=EvtInfo_AutoCreatedDemEvent_NVM_E_VERIFY_FAILED.GetEventTested
        OpEventGetEventTested_GetEventTested_EvtInfo_AutoCreatedDemEvent_NVM_E_WRITE_PROTECTED: start-on-event=GetEventTested, operation=EvtInfo_AutoCreatedDemEvent_NVM_E_WRITE_PROTECTED.GetEventTested
        OpEventGetEventTested_GetEventTested_EvtInfo_AutoCreatedDemEvent_NVM_E_WRONG_BLOCK_ID: start-on-event=GetEventTested, operation=EvtInfo_AutoCreatedDemEvent_NVM_E_WRONG_BLOCK_ID.GetEventTested
        OpEventGetEventTested_GetEventTested_EvtInfo_AutoCreatedDemEvent_WdgMConfigSet_WDGM_E_IMPROPER_CALLER: start-on-event=GetEventTested, operation=EvtInfo_AutoCreatedDemEvent_WdgMConfigSet_WDGM_E_IMPROPER_CALLER.GetEventTested
        OpEventGetEventTested_GetEventTested_EvtInfo_AutoCreatedDemEvent_WdgMConfigSet_WDGM_E_MONITORING: start-on-event=GetEventTested, operation=EvtInfo_AutoCreatedDemEvent_WdgMConfigSet_WDGM_E_MONITORING.GetEventTested
        OpEventGetEventTested_GetEventTested_EvtInfo_AutoCreatedDemEvent_WdgMConfigSet_WDGM_E_SET_MODE: start-on-event=GetEventTested, operation=EvtInfo_AutoCreatedDemEvent_WdgMConfigSet_WDGM_E_SET_MODE.GetEventTested
        OpEventGetEventTested_GetEventTested_EvtInfo_DemEventParameter_MCU_CLOCK_FAILURE: start-on-event=GetEventTested, operation=EvtInfo_DemEventParameter_MCU_CLOCK_FAILURE.GetEventTested
        OpEventGetEventTested_GetEventTested_EvtInfo_DemEventParameter_MCU_WRITE_TIMEOUT_FAILURE: start-on-event=GetEventTested, operation=EvtInfo_DemEventParameter_MCU_WRITE_TIMEOUT_FAILURE.GetEventTested
        OpEventGetEventTested_GetEventTested_EvtInfo_AutoCreatedDemEvent_FlsConfigSet_FLS_E_COMPARE_FAILED: start-on-event=GetEventTested, operation=EvtInfo_AutoCreatedDemEvent_FlsConfigSet_FLS_E_COMPARE_FAILED.GetEventTested
        OpEventGetEventTested_GetEventTested_EvtInfo_AutoCreatedDemEvent_FlsConfigSet_FLS_E_ERASE_FAILED: start-on-event=GetEventTested, operation=EvtInfo_AutoCreatedDemEvent_FlsConfigSet_FLS_E_ERASE_FAILED.GetEventTested
        OpEventGetEventTested_GetEventTested_EvtInfo_AutoCreatedDemEvent_FlsConfigSet_FLS_E_READ_FAILED: start-on-event=GetEventTested, operation=EvtInfo_AutoCreatedDemEvent_FlsConfigSet_FLS_E_READ_FAILED.GetEventTested
        OpEventGetEventTested_GetEventTested_EvtInfo_AutoCreatedDemEvent_FlsConfigSet_FLS_E_UNEXPECTED_FLASH_ID: start-on-event=GetEventTested, operation=EvtInfo_AutoCreatedDemEvent_FlsConfigSet_FLS_E_UNEXPECTED_FLASH_ID.GetEventTested
        OpEventGetEventTested_GetEventTested_EvtInfo_AutoCreatedDemEvent_FlsConfigSet_FLS_E_WRITE_FAILED: start-on-event=GetEventTested, operation=EvtInfo_AutoCreatedDemEvent_FlsConfigSet_FLS_E_WRITE_FAILED.GetEventTested
        OpEventGetEventTested_GetEventTested_EvtInfo_AutoCreatedDemEvent_WDG_E_DISABLE_REJECTED: start-on-event=GetEventTested, operation=EvtInfo_AutoCreatedDemEvent_WDG_E_DISABLE_REJECTED.GetEventTested
        OpEventGetEventTested_GetEventTested_EvtInfo_AutoCreatedDemEvent_WDG_E_MODE_FAILED: start-on-event=GetEventTested, operation=EvtInfo_AutoCreatedDemEvent_WDG_E_MODE_FAILED.GetEventTested
        OpEventGetEventTested_GetEventTested_EvtInfo_AutoCreatedDemEvent_FlsConfigSet_FLS_E_READ_FAILED_DED: start-on-event=GetEventTested, operation=EvtInfo_AutoCreatedDemEvent_FlsConfigSet_FLS_E_READ_FAILED_DED.GetEventTested
        OpEventGetEventTested_GetEventTested_EvtInfo_DemEventParameter_PORT_WRITE_TIMEOUT_FAILURE: start-on-event=GetEventTested, operation=EvtInfo_DemEventParameter_PORT_WRITE_TIMEOUT_FAILURE.GetEventTested
        OpEventGetEventTested_GetEventTested_EvtInfo_DemEventParameter_WDG_TRIGGER_TIMEOUT: start-on-event=GetEventTested, operation=EvtInfo_DemEventParameter_WDG_TRIGGER_TIMEOUT.GetEventTested
        OpEventGetEventTested_GetEventTested_EvtInfo_AutoCreatedDemEvent_SpiDriver_SPI_E_HARDWARE_ERROR: start-on-event=GetEventTested, operation=EvtInfo_AutoCreatedDemEvent_SpiDriver_SPI_E_HARDWARE_ERROR.GetEventTested
        OpEventGetEventTested_GetEventTested_EvtInfo_AutoCreatedDemEvent_SpiDriver_SPI_E_DATA_TX_TIMEOUT_FAILURE: start-on-event=GetEventTested, operation=EvtInfo_AutoCreatedDemEvent_SpiDriver_SPI_E_DATA_TX_TIMEOUT_FAILURE.GetEventTested
        OpEventGetEventTested_GetEventTested_EvtInfo_AutoCreatedDemEvent_CSM_E_INIT_FAILED: start-on-event=GetEventTested, operation=EvtInfo_AutoCreatedDemEvent_CSM_E_INIT_FAILED.GetEventTested
        OpEventGetEventTested_GetEventTested_EvtInfo_RAMTST_E_RAM_FAILURE: start-on-event=GetEventTested, operation=EvtInfo_RAMTST_E_RAM_FAILURE.GetEventTested
        OpEventGetEventTested_GetEventTested_EvtInfo_AutoCreatedDemEvent_WdgMConfigSet_WDGM_E_IMPROPER_CALLER_1: start-on-event=GetEventTested, operation=EvtInfo_AutoCreatedDemEvent_WdgMConfigSet_WDGM_E_IMPROPER_CALLER_1.GetEventTested
        OpEventGetEventTested_GetEventTested_EvtInfo_AutoCreatedDemEvent_WdgMConfigSet_WDGM_E_MONITORING_1: start-on-event=GetEventTested, operation=EvtInfo_AutoCreatedDemEvent_WdgMConfigSet_WDGM_E_MONITORING_1.GetEventTested
        OpEventGetEventTested_GetEventTested_EvtInfo_AutoCreatedDemEvent_WdgMConfigSet_WDGM_E_SET_MODE_1: start-on-event=GetEventTested, operation=EvtInfo_AutoCreatedDemEvent_WdgMConfigSet_WDGM_E_SET_MODE_1.GetEventTested
        OpEventGetEventTested_GetEventTested_EvtInfo_DemEventParameter_GPT_E_TIMEOUT: start-on-event=GetEventTested, operation=EvtInfo_DemEventParameter_GPT_E_TIMEOUT.GetEventTested
        OpEventGetEventTested_GetEventTested_Event_DemEventParameter_GPT_E_TIMEOUT: start-on-event=GetEventTested, operation=Event_DemEventParameter_GPT_E_TIMEOUT.GetEventTested
        OpEventGetDTCOfEvent_GetDTCOfEvent_GeneralEventInfo: start-on-event=GetDTCOfEvent, operation=GeneralEventInfo.GetDTCOfEvent
        OpEventGetDTCOfEvent_GetDTCOfEvent_EvtInfo_DTC_0xF00316: start-on-event=GetDTCOfEvent, operation=EvtInfo_DTC_0xF00316.GetDTCOfEvent
        OpEventGetDTCOfEvent_GetDTCOfEvent_Event_DTC_0xF00316: start-on-event=GetDTCOfEvent, operation=Event_DTC_0xF00316.GetDTCOfEvent
        OpEventGetDTCOfEvent_GetDTCOfEvent_EvtInfo_DTC_0xC19800: start-on-event=GetDTCOfEvent, operation=EvtInfo_DTC_0xC19800.GetDTCOfEvent
        OpEventGetDTCOfEvent_GetDTCOfEvent_Event_DTC_0xC19800: start-on-event=GetDTCOfEvent, operation=Event_DTC_0xC19800.GetDTCOfEvent
        OpEventGetDTCOfEvent_GetDTCOfEvent_EvtInfo_DTC_0xF00317: start-on-event=GetDTCOfEvent, operation=EvtInfo_DTC_0xF00317.GetDTCOfEvent
        OpEventGetDTCOfEvent_GetDTCOfEvent_Event_DTC_0xF00317: start-on-event=GetDTCOfEvent, operation=Event_DTC_0xF00317.GetDTCOfEvent
        OpEventGetDTCOfEvent_GetDTCOfEvent_EvtInfo_DTC_0xC14600: start-on-event=GetDTCOfEvent, operation=EvtInfo_DTC_0xC14600.GetDTCOfEvent
        OpEventGetDTCOfEvent_GetDTCOfEvent_Event_DTC_0xC14600: start-on-event=GetDTCOfEvent, operation=Event_DTC_0xC14600.GetDTCOfEvent
        OpEventGetDTCOfEvent_GetDTCOfEvent_EvtInfo_DTC_0xC18600: start-on-event=GetDTCOfEvent, operation=EvtInfo_DTC_0xC18600.GetDTCOfEvent
        OpEventGetDTCOfEvent_GetDTCOfEvent_Event_DTC_0xC18600: start-on-event=GetDTCOfEvent, operation=Event_DTC_0xC18600.GetDTCOfEvent
        OpEventGetDTCOfEvent_GetDTCOfEvent_EvtInfo_DTC_0xD96200: start-on-event=GetDTCOfEvent, operation=EvtInfo_DTC_0xD96200.GetDTCOfEvent
        OpEventGetDTCOfEvent_GetDTCOfEvent_Event_DTC_0xD96200: start-on-event=GetDTCOfEvent, operation=Event_DTC_0xD96200.GetDTCOfEvent
        OpEventGetDTCOfEvent_GetDTCOfEvent_EvtInfo_DTC_0xC18400: start-on-event=GetDTCOfEvent, operation=EvtInfo_DTC_0xC18400.GetDTCOfEvent
        OpEventGetDTCOfEvent_GetDTCOfEvent_Event_DTC_0xC18400: start-on-event=GetDTCOfEvent, operation=Event_DTC_0xC18400.GetDTCOfEvent
        OpEventGetDTCOfEvent_GetDTCOfEvent_EvtInfo_DTC_0xC15500: start-on-event=GetDTCOfEvent, operation=EvtInfo_DTC_0xC15500.GetDTCOfEvent
        OpEventGetDTCOfEvent_GetDTCOfEvent_Event_DTC_0xC15500: start-on-event=GetDTCOfEvent, operation=Event_DTC_0xC15500.GetDTCOfEvent
        OpEventGetDTCOfEvent_GetDTCOfEvent_EvtInfo_DTC_0xC07700: start-on-event=GetDTCOfEvent, operation=EvtInfo_DTC_0xC07700.GetDTCOfEvent
        OpEventGetDTCOfEvent_GetDTCOfEvent_Event_DTC_0xC07700: start-on-event=GetDTCOfEvent, operation=Event_DTC_0xC07700.GetDTCOfEvent
        OpEventGetDTCOfEvent_GetDTCOfEvent_EvtInfo_DTC_0xC16400: start-on-event=GetDTCOfEvent, operation=EvtInfo_DTC_0xC16400.GetDTCOfEvent
        OpEventGetDTCOfEvent_GetDTCOfEvent_Event_DTC_0xC16400: start-on-event=GetDTCOfEvent, operation=Event_DTC_0xC16400.GetDTCOfEvent
        OpEventGetDTCOfEvent_GetDTCOfEvent_EvtInfo_AutoCreatedDemEvent_CAN_5_PhysicalChannel_09246746_CANSM_E_BUS_OFF: start-on-event=GetDTCOfEvent, operation=EvtInfo_AutoCreatedDemEvent_CAN_5_PhysicalChannel_09246746_CANSM_E_BUS_OFF.GetDTCOfEvent
        OpEventGetDTCOfEvent_GetDTCOfEvent_EvtInfo_AutoCreatedDemEvent_EcuMConfiguration_ECUM_E_ALL_RUN_REQUESTS_KILLED: start-on-event=GetDTCOfEvent, operation=EvtInfo_AutoCreatedDemEvent_EcuMConfiguration_ECUM_E_ALL_RUN_REQUESTS_KILLED.GetDTCOfEvent
        OpEventGetDTCOfEvent_GetDTCOfEvent_EvtInfo_AutoCreatedDemEvent_EcuMConfiguration_ECUM_E_CONFIGURATION_DATA_INCONSISTENT: start-on-event=GetDTCOfEvent, operation=EvtInfo_AutoCreatedDemEvent_EcuMConfiguration_ECUM_E_CONFIGURATION_DATA_INCONSISTENT.GetDTCOfEvent
        OpEventGetDTCOfEvent_GetDTCOfEvent_EvtInfo_AutoCreatedDemEvent_EcuMConfiguration_ECUM_E_RAM_CHECK_FAILED: start-on-event=GetDTCOfEvent, operation=EvtInfo_AutoCreatedDemEvent_EcuMConfiguration_ECUM_E_RAM_CHECK_FAILED.GetDTCOfEvent
        OpEventGetDTCOfEvent_GetDTCOfEvent_EvtInfo_AutoCreatedDemEvent_EcuMConfiguration_ECUM_E_IMPROPER_CALLER: start-on-event=GetDTCOfEvent, operation=EvtInfo_AutoCreatedDemEvent_EcuMConfiguration_ECUM_E_IMPROPER_CALLER.GetDTCOfEvent
        OpEventGetDTCOfEvent_GetDTCOfEvent_EvtInfo_AutoCreatedDemEvent_NVM_E_INTEGRITY_FAILED: start-on-event=GetDTCOfEvent, operation=EvtInfo_AutoCreatedDemEvent_NVM_E_INTEGRITY_FAILED.GetDTCOfEvent
        OpEventGetDTCOfEvent_GetDTCOfEvent_EvtInfo_AutoCreatedDemEvent_NVM_E_LOSS_OF_REDUNDANCY: start-on-event=GetDTCOfEvent, operation=EvtInfo_AutoCreatedDemEvent_NVM_E_LOSS_OF_REDUNDANCY.GetDTCOfEvent
        OpEventGetDTCOfEvent_GetDTCOfEvent_EvtInfo_AutoCreatedDemEvent_NVM_E_QUEUE_OVERFLOW: start-on-event=GetDTCOfEvent, operation=EvtInfo_AutoCreatedDemEvent_NVM_E_QUEUE_OVERFLOW.GetDTCOfEvent
        OpEventGetDTCOfEvent_GetDTCOfEvent_EvtInfo_AutoCreatedDemEvent_NVM_E_REQ_FAILED: start-on-event=GetDTCOfEvent, operation=EvtInfo_AutoCreatedDemEvent_NVM_E_REQ_FAILED.GetDTCOfEvent
        OpEventGetDTCOfEvent_GetDTCOfEvent_EvtInfo_AutoCreatedDemEvent_NVM_E_VERIFY_FAILED: start-on-event=GetDTCOfEvent, operation=EvtInfo_AutoCreatedDemEvent_NVM_E_VERIFY_FAILED.GetDTCOfEvent
        OpEventGetDTCOfEvent_GetDTCOfEvent_EvtInfo_AutoCreatedDemEvent_NVM_E_WRITE_PROTECTED: start-on-event=GetDTCOfEvent, operation=EvtInfo_AutoCreatedDemEvent_NVM_E_WRITE_PROTECTED.GetDTCOfEvent
        OpEventGetDTCOfEvent_GetDTCOfEvent_EvtInfo_AutoCreatedDemEvent_NVM_E_WRONG_BLOCK_ID: start-on-event=GetDTCOfEvent, operation=EvtInfo_AutoCreatedDemEvent_NVM_E_WRONG_BLOCK_ID.GetDTCOfEvent
        OpEventGetDTCOfEvent_GetDTCOfEvent_EvtInfo_AutoCreatedDemEvent_WdgMConfigSet_WDGM_E_IMPROPER_CALLER: start-on-event=GetDTCOfEvent, operation=EvtInfo_AutoCreatedDemEvent_WdgMConfigSet_WDGM_E_IMPROPER_CALLER.GetDTCOfEvent
        OpEventGetDTCOfEvent_GetDTCOfEvent_EvtInfo_AutoCreatedDemEvent_WdgMConfigSet_WDGM_E_MONITORING: start-on-event=GetDTCOfEvent, operation=EvtInfo_AutoCreatedDemEvent_WdgMConfigSet_WDGM_E_MONITORING.GetDTCOfEvent
        OpEventGetDTCOfEvent_GetDTCOfEvent_EvtInfo_AutoCreatedDemEvent_WdgMConfigSet_WDGM_E_SET_MODE: start-on-event=GetDTCOfEvent, operation=EvtInfo_AutoCreatedDemEvent_WdgMConfigSet_WDGM_E_SET_MODE.GetDTCOfEvent
        OpEventGetDTCOfEvent_GetDTCOfEvent_EvtInfo_DemEventParameter_MCU_CLOCK_FAILURE: start-on-event=GetDTCOfEvent, operation=EvtInfo_DemEventParameter_MCU_CLOCK_FAILURE.GetDTCOfEvent
        OpEventGetDTCOfEvent_GetDTCOfEvent_EvtInfo_DemEventParameter_MCU_WRITE_TIMEOUT_FAILURE: start-on-event=GetDTCOfEvent, operation=EvtInfo_DemEventParameter_MCU_WRITE_TIMEOUT_FAILURE.GetDTCOfEvent
        OpEventGetDTCOfEvent_GetDTCOfEvent_EvtInfo_AutoCreatedDemEvent_FlsConfigSet_FLS_E_COMPARE_FAILED: start-on-event=GetDTCOfEvent, operation=EvtInfo_AutoCreatedDemEvent_FlsConfigSet_FLS_E_COMPARE_FAILED.GetDTCOfEvent
        OpEventGetDTCOfEvent_GetDTCOfEvent_EvtInfo_AutoCreatedDemEvent_FlsConfigSet_FLS_E_ERASE_FAILED: start-on-event=GetDTCOfEvent, operation=EvtInfo_AutoCreatedDemEvent_FlsConfigSet_FLS_E_ERASE_FAILED.GetDTCOfEvent
        OpEventGetDTCOfEvent_GetDTCOfEvent_EvtInfo_AutoCreatedDemEvent_FlsConfigSet_FLS_E_READ_FAILED: start-on-event=GetDTCOfEvent, operation=EvtInfo_AutoCreatedDemEvent_FlsConfigSet_FLS_E_READ_FAILED.GetDTCOfEvent
        OpEventGetDTCOfEvent_GetDTCOfEvent_EvtInfo_AutoCreatedDemEvent_FlsConfigSet_FLS_E_UNEXPECTED_FLASH_ID: start-on-event=GetDTCOfEvent, operation=EvtInfo_AutoCreatedDemEvent_FlsConfigSet_FLS_E_UNEXPECTED_FLASH_ID.GetDTCOfEvent
        OpEventGetDTCOfEvent_GetDTCOfEvent_EvtInfo_AutoCreatedDemEvent_FlsConfigSet_FLS_E_WRITE_FAILED: start-on-event=GetDTCOfEvent, operation=EvtInfo_AutoCreatedDemEvent_FlsConfigSet_FLS_E_WRITE_FAILED.GetDTCOfEvent
        OpEventGetDTCOfEvent_GetDTCOfEvent_EvtInfo_AutoCreatedDemEvent_WDG_E_DISABLE_REJECTED: start-on-event=GetDTCOfEvent, operation=EvtInfo_AutoCreatedDemEvent_WDG_E_DISABLE_REJECTED.GetDTCOfEvent
        OpEventGetDTCOfEvent_GetDTCOfEvent_EvtInfo_AutoCreatedDemEvent_WDG_E_MODE_FAILED: start-on-event=GetDTCOfEvent, operation=EvtInfo_AutoCreatedDemEvent_WDG_E_MODE_FAILED.GetDTCOfEvent
        OpEventGetDTCOfEvent_GetDTCOfEvent_EvtInfo_AutoCreatedDemEvent_FlsConfigSet_FLS_E_READ_FAILED_DED: start-on-event=GetDTCOfEvent, operation=EvtInfo_AutoCreatedDemEvent_FlsConfigSet_FLS_E_READ_FAILED_DED.GetDTCOfEvent
        OpEventGetDTCOfEvent_GetDTCOfEvent_EvtInfo_DemEventParameter_PORT_WRITE_TIMEOUT_FAILURE: start-on-event=GetDTCOfEvent, operation=EvtInfo_DemEventParameter_PORT_WRITE_TIMEOUT_FAILURE.GetDTCOfEvent
        OpEventGetDTCOfEvent_GetDTCOfEvent_EvtInfo_DemEventParameter_WDG_TRIGGER_TIMEOUT: start-on-event=GetDTCOfEvent, operation=EvtInfo_DemEventParameter_WDG_TRIGGER_TIMEOUT.GetDTCOfEvent
        OpEventGetDTCOfEvent_GetDTCOfEvent_EvtInfo_AutoCreatedDemEvent_SpiDriver_SPI_E_HARDWARE_ERROR: start-on-event=GetDTCOfEvent, operation=EvtInfo_AutoCreatedDemEvent_SpiDriver_SPI_E_HARDWARE_ERROR.GetDTCOfEvent
        OpEventGetDTCOfEvent_GetDTCOfEvent_EvtInfo_AutoCreatedDemEvent_SpiDriver_SPI_E_DATA_TX_TIMEOUT_FAILURE: start-on-event=GetDTCOfEvent, operation=EvtInfo_AutoCreatedDemEvent_SpiDriver_SPI_E_DATA_TX_TIMEOUT_FAILURE.GetDTCOfEvent
        OpEventGetDTCOfEvent_GetDTCOfEvent_EvtInfo_AutoCreatedDemEvent_CSM_E_INIT_FAILED: start-on-event=GetDTCOfEvent, operation=EvtInfo_AutoCreatedDemEvent_CSM_E_INIT_FAILED.GetDTCOfEvent
        OpEventGetDTCOfEvent_GetDTCOfEvent_EvtInfo_RAMTST_E_RAM_FAILURE: start-on-event=GetDTCOfEvent, operation=EvtInfo_RAMTST_E_RAM_FAILURE.GetDTCOfEvent
        OpEventGetDTCOfEvent_GetDTCOfEvent_EvtInfo_AutoCreatedDemEvent_WdgMConfigSet_WDGM_E_IMPROPER_CALLER_1: start-on-event=GetDTCOfEvent, operation=EvtInfo_AutoCreatedDemEvent_WdgMConfigSet_WDGM_E_IMPROPER_CALLER_1.GetDTCOfEvent
        OpEventGetDTCOfEvent_GetDTCOfEvent_EvtInfo_AutoCreatedDemEvent_WdgMConfigSet_WDGM_E_MONITORING_1: start-on-event=GetDTCOfEvent, operation=EvtInfo_AutoCreatedDemEvent_WdgMConfigSet_WDGM_E_MONITORING_1.GetDTCOfEvent
        OpEventGetDTCOfEvent_GetDTCOfEvent_EvtInfo_AutoCreatedDemEvent_WdgMConfigSet_WDGM_E_SET_MODE_1: start-on-event=GetDTCOfEvent, operation=EvtInfo_AutoCreatedDemEvent_WdgMConfigSet_WDGM_E_SET_MODE_1.GetDTCOfEvent
        OpEventGetDTCOfEvent_GetDTCOfEvent_EvtInfo_DemEventParameter_GPT_E_TIMEOUT: start-on-event=GetDTCOfEvent, operation=EvtInfo_DemEventParameter_GPT_E_TIMEOUT.GetDTCOfEvent
        OpEventGetDTCOfEvent_GetDTCOfEvent_Event_DemEventParameter_GPT_E_TIMEOUT: start-on-event=GetDTCOfEvent, operation=Event_DemEventParameter_GPT_E_TIMEOUT.GetDTCOfEvent
        OpEventGetFaultDetectionCounter_GetFaultDetectionCounter_GeneralEventInfo: start-on-event=GetFaultDetectionCounter, operation=GeneralEventInfo.GetFaultDetectionCounter
        OpEventGetFaultDetectionCounter_GetFaultDetectionCounter_EvtInfo_DTC_0xF00316: start-on-event=GetFaultDetectionCounter, operation=EvtInfo_DTC_0xF00316.GetFaultDetectionCounter
        OpEventGetFaultDetectionCounter_GetFaultDetectionCounter_Event_DTC_0xF00316: start-on-event=GetFaultDetectionCounter, operation=Event_DTC_0xF00316.GetFaultDetectionCounter
        OpEventGetFaultDetectionCounter_GetFaultDetectionCounter_EvtInfo_DTC_0xC19800: start-on-event=GetFaultDetectionCounter, operation=EvtInfo_DTC_0xC19800.GetFaultDetectionCounter
        OpEventGetFaultDetectionCounter_GetFaultDetectionCounter_Event_DTC_0xC19800: start-on-event=GetFaultDetectionCounter, operation=Event_DTC_0xC19800.GetFaultDetectionCounter
        OpEventGetFaultDetectionCounter_GetFaultDetectionCounter_EvtInfo_DTC_0xF00317: start-on-event=GetFaultDetectionCounter, operation=EvtInfo_DTC_0xF00317.GetFaultDetectionCounter
        OpEventGetFaultDetectionCounter_GetFaultDetectionCounter_Event_DTC_0xF00317: start-on-event=GetFaultDetectionCounter, operation=Event_DTC_0xF00317.GetFaultDetectionCounter
        OpEventGetFaultDetectionCounter_GetFaultDetectionCounter_EvtInfo_DTC_0xC14600: start-on-event=GetFaultDetectionCounter, operation=EvtInfo_DTC_0xC14600.GetFaultDetectionCounter
        OpEventGetFaultDetectionCounter_GetFaultDetectionCounter_Event_DTC_0xC14600: start-on-event=GetFaultDetectionCounter, operation=Event_DTC_0xC14600.GetFaultDetectionCounter
        OpEventGetFaultDetectionCounter_GetFaultDetectionCounter_EvtInfo_DTC_0xC18600: start-on-event=GetFaultDetectionCounter, operation=EvtInfo_DTC_0xC18600.GetFaultDetectionCounter
        OpEventGetFaultDetectionCounter_GetFaultDetectionCounter_Event_DTC_0xC18600: start-on-event=GetFaultDetectionCounter, operation=Event_DTC_0xC18600.GetFaultDetectionCounter
        OpEventGetFaultDetectionCounter_GetFaultDetectionCounter_EvtInfo_DTC_0xD96200: start-on-event=GetFaultDetectionCounter, operation=EvtInfo_DTC_0xD96200.GetFaultDetectionCounter
        OpEventGetFaultDetectionCounter_GetFaultDetectionCounter_Event_DTC_0xD96200: start-on-event=GetFaultDetectionCounter, operation=Event_DTC_0xD96200.GetFaultDetectionCounter
        OpEventGetFaultDetectionCounter_GetFaultDetectionCounter_EvtInfo_DTC_0xC18400: start-on-event=GetFaultDetectionCounter, operation=EvtInfo_DTC_0xC18400.GetFaultDetectionCounter
        OpEventGetFaultDetectionCounter_GetFaultDetectionCounter_Event_DTC_0xC18400: start-on-event=GetFaultDetectionCounter, operation=Event_DTC_0xC18400.GetFaultDetectionCounter
        OpEventGetFaultDetectionCounter_GetFaultDetectionCounter_EvtInfo_DTC_0xC15500: start-on-event=GetFaultDetectionCounter, operation=EvtInfo_DTC_0xC15500.GetFaultDetectionCounter
        OpEventGetFaultDetectionCounter_GetFaultDetectionCounter_Event_DTC_0xC15500: start-on-event=GetFaultDetectionCounter, operation=Event_DTC_0xC15500.GetFaultDetectionCounter
        OpEventGetFaultDetectionCounter_GetFaultDetectionCounter_EvtInfo_DTC_0xC07700: start-on-event=GetFaultDetectionCounter, operation=EvtInfo_DTC_0xC07700.GetFaultDetectionCounter
        OpEventGetFaultDetectionCounter_GetFaultDetectionCounter_Event_DTC_0xC07700: start-on-event=GetFaultDetectionCounter, operation=Event_DTC_0xC07700.GetFaultDetectionCounter
        OpEventGetFaultDetectionCounter_GetFaultDetectionCounter_EvtInfo_DTC_0xC16400: start-on-event=GetFaultDetectionCounter, operation=EvtInfo_DTC_0xC16400.GetFaultDetectionCounter
        OpEventGetFaultDetectionCounter_GetFaultDetectionCounter_Event_DTC_0xC16400: start-on-event=GetFaultDetectionCounter, operation=Event_DTC_0xC16400.GetFaultDetectionCounter
        OpEventGetFaultDetectionCounter_GetFaultDetectionCounter_EvtInfo_AutoCreatedDemEvent_CAN_5_PhysicalChannel_09246746_CAN_b7410900: start-on-event=GetFaultDetectionCounter, operation=EvtInfo_AutoCreatedDemEvent_CAN_5_PhysicalChannel_09246746_CANSM_E_BUS_OFF.GetFaultDetectionCounter
        OpEventGetFaultDetectionCounter_GetFaultDetectionCounter_EvtInfo_AutoCreatedDemEvent_EcuMConfiguration_ECUM_E_ALL_RUN_R_5c1d7bad: start-on-event=GetFaultDetectionCounter, operation=EvtInfo_AutoCreatedDemEvent_EcuMConfiguration_ECUM_E_ALL_RUN_REQUESTS_KILLED.GetFaultDetectionCounter
        OpEventGetFaultDetectionCounter_GetFaultDetectionCounter_EvtInfo_AutoCreatedDemEvent_EcuMConfiguration_ECUM_E_CONFIGURA_55d3b4f6: start-on-event=GetFaultDetectionCounter, operation=EvtInfo_AutoCreatedDemEvent_EcuMConfiguration_ECUM_E_CONFIGURATION_DATA_INCONSISTENT.GetFaultDetectionCounter
        OpEventGetFaultDetectionCounter_GetFaultDetectionCounter_EvtInfo_AutoCreatedDemEvent_EcuMConfiguration_ECUM_E_RAM_CHECK_FAILED: start-on-event=GetFaultDetectionCounter, operation=EvtInfo_AutoCreatedDemEvent_EcuMConfiguration_ECUM_E_RAM_CHECK_FAILED.GetFaultDetectionCounter
        OpEventGetFaultDetectionCounter_GetFaultDetectionCounter_EvtInfo_AutoCreatedDemEvent_EcuMConfiguration_ECUM_E_IMPROPER_CALLER: start-on-event=GetFaultDetectionCounter, operation=EvtInfo_AutoCreatedDemEvent_EcuMConfiguration_ECUM_E_IMPROPER_CALLER.GetFaultDetectionCounter
        OpEventGetFaultDetectionCounter_GetFaultDetectionCounter_EvtInfo_AutoCreatedDemEvent_NVM_E_INTEGRITY_FAILED: start-on-event=GetFaultDetectionCounter, operation=EvtInfo_AutoCreatedDemEvent_NVM_E_INTEGRITY_FAILED.GetFaultDetectionCounter
        OpEventGetFaultDetectionCounter_GetFaultDetectionCounter_EvtInfo_AutoCreatedDemEvent_NVM_E_LOSS_OF_REDUNDANCY: start-on-event=GetFaultDetectionCounter, operation=EvtInfo_AutoCreatedDemEvent_NVM_E_LOSS_OF_REDUNDANCY.GetFaultDetectionCounter
        OpEventGetFaultDetectionCounter_GetFaultDetectionCounter_EvtInfo_AutoCreatedDemEvent_NVM_E_QUEUE_OVERFLOW: start-on-event=GetFaultDetectionCounter, operation=EvtInfo_AutoCreatedDemEvent_NVM_E_QUEUE_OVERFLOW.GetFaultDetectionCounter
        OpEventGetFaultDetectionCounter_GetFaultDetectionCounter_EvtInfo_AutoCreatedDemEvent_NVM_E_REQ_FAILED: start-on-event=GetFaultDetectionCounter, operation=EvtInfo_AutoCreatedDemEvent_NVM_E_REQ_FAILED.GetFaultDetectionCounter
        OpEventGetFaultDetectionCounter_GetFaultDetectionCounter_EvtInfo_AutoCreatedDemEvent_NVM_E_VERIFY_FAILED: start-on-event=GetFaultDetectionCounter, operation=EvtInfo_AutoCreatedDemEvent_NVM_E_VERIFY_FAILED.GetFaultDetectionCounter
        OpEventGetFaultDetectionCounter_GetFaultDetectionCounter_EvtInfo_AutoCreatedDemEvent_NVM_E_WRITE_PROTECTED: start-on-event=GetFaultDetectionCounter, operation=EvtInfo_AutoCreatedDemEvent_NVM_E_WRITE_PROTECTED.GetFaultDetectionCounter
        OpEventGetFaultDetectionCounter_GetFaultDetectionCounter_EvtInfo_AutoCreatedDemEvent_NVM_E_WRONG_BLOCK_ID: start-on-event=GetFaultDetectionCounter, operation=EvtInfo_AutoCreatedDemEvent_NVM_E_WRONG_BLOCK_ID.GetFaultDetectionCounter
        OpEventGetFaultDetectionCounter_GetFaultDetectionCounter_EvtInfo_AutoCreatedDemEvent_WdgMConfigSet_WDGM_E_IMPROPER_CALLER: start-on-event=GetFaultDetectionCounter, operation=EvtInfo_AutoCreatedDemEvent_WdgMConfigSet_WDGM_E_IMPROPER_CALLER.GetFaultDetectionCounter
        OpEventGetFaultDetectionCounter_GetFaultDetectionCounter_EvtInfo_AutoCreatedDemEvent_WdgMConfigSet_WDGM_E_MONITORING: start-on-event=GetFaultDetectionCounter, operation=EvtInfo_AutoCreatedDemEvent_WdgMConfigSet_WDGM_E_MONITORING.GetFaultDetectionCounter
        OpEventGetFaultDetectionCounter_GetFaultDetectionCounter_EvtInfo_AutoCreatedDemEvent_WdgMConfigSet_WDGM_E_SET_MODE: start-on-event=GetFaultDetectionCounter, operation=EvtInfo_AutoCreatedDemEvent_WdgMConfigSet_WDGM_E_SET_MODE.GetFaultDetectionCounter
        OpEventGetFaultDetectionCounter_GetFaultDetectionCounter_EvtInfo_DemEventParameter_MCU_CLOCK_FAILURE: start-on-event=GetFaultDetectionCounter, operation=EvtInfo_DemEventParameter_MCU_CLOCK_FAILURE.GetFaultDetectionCounter
        OpEventGetFaultDetectionCounter_GetFaultDetectionCounter_EvtInfo_DemEventParameter_MCU_WRITE_TIMEOUT_FAILURE: start-on-event=GetFaultDetectionCounter, operation=EvtInfo_DemEventParameter_MCU_WRITE_TIMEOUT_FAILURE.GetFaultDetectionCounter
        OpEventGetFaultDetectionCounter_GetFaultDetectionCounter_EvtInfo_AutoCreatedDemEvent_FlsConfigSet_FLS_E_COMPARE_FAILED: start-on-event=GetFaultDetectionCounter, operation=EvtInfo_AutoCreatedDemEvent_FlsConfigSet_FLS_E_COMPARE_FAILED.GetFaultDetectionCounter
        OpEventGetFaultDetectionCounter_GetFaultDetectionCounter_EvtInfo_AutoCreatedDemEvent_FlsConfigSet_FLS_E_ERASE_FAILED: start-on-event=GetFaultDetectionCounter, operation=EvtInfo_AutoCreatedDemEvent_FlsConfigSet_FLS_E_ERASE_FAILED.GetFaultDetectionCounter
        OpEventGetFaultDetectionCounter_GetFaultDetectionCounter_EvtInfo_AutoCreatedDemEvent_FlsConfigSet_FLS_E_READ_FAILED: start-on-event=GetFaultDetectionCounter, operation=EvtInfo_AutoCreatedDemEvent_FlsConfigSet_FLS_E_READ_FAILED.GetFaultDetectionCounter
        OpEventGetFaultDetectionCounter_GetFaultDetectionCounter_EvtInfo_AutoCreatedDemEvent_FlsConfigSet_FLS_E_UNEXPECTED_FLASH_ID: start-on-event=GetFaultDetectionCounter, operation=EvtInfo_AutoCreatedDemEvent_FlsConfigSet_FLS_E_UNEXPECTED_FLASH_ID.GetFaultDetectionCounter
        OpEventGetFaultDetectionCounter_GetFaultDetectionCounter_EvtInfo_AutoCreatedDemEvent_FlsConfigSet_FLS_E_WRITE_FAILED: start-on-event=GetFaultDetectionCounter, operation=EvtInfo_AutoCreatedDemEvent_FlsConfigSet_FLS_E_WRITE_FAILED.GetFaultDetectionCounter
        OpEventGetFaultDetectionCounter_GetFaultDetectionCounter_EvtInfo_AutoCreatedDemEvent_WDG_E_DISABLE_REJECTED: start-on-event=GetFaultDetectionCounter, operation=EvtInfo_AutoCreatedDemEvent_WDG_E_DISABLE_REJECTED.GetFaultDetectionCounter
        OpEventGetFaultDetectionCounter_GetFaultDetectionCounter_EvtInfo_AutoCreatedDemEvent_WDG_E_MODE_FAILED: start-on-event=GetFaultDetectionCounter, operation=EvtInfo_AutoCreatedDemEvent_WDG_E_MODE_FAILED.GetFaultDetectionCounter
        OpEventGetFaultDetectionCounter_GetFaultDetectionCounter_EvtInfo_AutoCreatedDemEvent_FlsConfigSet_FLS_E_READ_FAILED_DED: start-on-event=GetFaultDetectionCounter, operation=EvtInfo_AutoCreatedDemEvent_FlsConfigSet_FLS_E_READ_FAILED_DED.GetFaultDetectionCounter
        OpEventGetFaultDetectionCounter_GetFaultDetectionCounter_EvtInfo_DemEventParameter_PORT_WRITE_TIMEOUT_FAILURE: start-on-event=GetFaultDetectionCounter, operation=EvtInfo_DemEventParameter_PORT_WRITE_TIMEOUT_FAILURE.GetFaultDetectionCounter
        OpEventGetFaultDetectionCounter_GetFaultDetectionCounter_EvtInfo_DemEventParameter_WDG_TRIGGER_TIMEOUT: start-on-event=GetFaultDetectionCounter, operation=EvtInfo_DemEventParameter_WDG_TRIGGER_TIMEOUT.GetFaultDetectionCounter
        OpEventGetFaultDetectionCounter_GetFaultDetectionCounter_EvtInfo_AutoCreatedDemEvent_SpiDriver_SPI_E_HARDWARE_ERROR: start-on-event=GetFaultDetectionCounter, operation=EvtInfo_AutoCreatedDemEvent_SpiDriver_SPI_E_HARDWARE_ERROR.GetFaultDetectionCounter
        OpEventGetFaultDetectionCounter_GetFaultDetectionCounter_EvtInfo_AutoCreatedDemEvent_SpiDriver_SPI_E_DATA_TX_TIMEOUT_FAILURE: start-on-event=GetFaultDetectionCounter, operation=EvtInfo_AutoCreatedDemEvent_SpiDriver_SPI_E_DATA_TX_TIMEOUT_FAILURE.GetFaultDetectionCounter
        OpEventGetFaultDetectionCounter_GetFaultDetectionCounter_EvtInfo_AutoCreatedDemEvent_CSM_E_INIT_FAILED: start-on-event=GetFaultDetectionCounter, operation=EvtInfo_AutoCreatedDemEvent_CSM_E_INIT_FAILED.GetFaultDetectionCounter
        OpEventGetFaultDetectionCounter_GetFaultDetectionCounter_EvtInfo_RAMTST_E_RAM_FAILURE: start-on-event=GetFaultDetectionCounter, operation=EvtInfo_RAMTST_E_RAM_FAILURE.GetFaultDetectionCounter
        OpEventGetFaultDetectionCounter_GetFaultDetectionCounter_EvtInfo_AutoCreatedDemEvent_WdgMConfigSet_WDGM_E_IMPROPER_CALLER_1: start-on-event=GetFaultDetectionCounter, operation=EvtInfo_AutoCreatedDemEvent_WdgMConfigSet_WDGM_E_IMPROPER_CALLER_1.GetFaultDetectionCounter
        OpEventGetFaultDetectionCounter_GetFaultDetectionCounter_EvtInfo_AutoCreatedDemEvent_WdgMConfigSet_WDGM_E_MONITORING_1: start-on-event=GetFaultDetectionCounter, operation=EvtInfo_AutoCreatedDemEvent_WdgMConfigSet_WDGM_E_MONITORING_1.GetFaultDetectionCounter
        OpEventGetFaultDetectionCounter_GetFaultDetectionCounter_EvtInfo_AutoCreatedDemEvent_WdgMConfigSet_WDGM_E_SET_MODE_1: start-on-event=GetFaultDetectionCounter, operation=EvtInfo_AutoCreatedDemEvent_WdgMConfigSet_WDGM_E_SET_MODE_1.GetFaultDetectionCounter
        OpEventGetFaultDetectionCounter_GetFaultDetectionCounter_EvtInfo_DemEventParameter_GPT_E_TIMEOUT: start-on-event=GetFaultDetectionCounter, operation=EvtInfo_DemEventParameter_GPT_E_TIMEOUT.GetFaultDetectionCounter
        OpEventGetFaultDetectionCounter_GetFaultDetectionCounter_Event_DemEventParameter_GPT_E_TIMEOUT: start-on-event=GetFaultDetectionCounter, operation=Event_DemEventParameter_GPT_E_TIMEOUT.GetFaultDetectionCounter
        OpEventGetEventFreezeFrameData_GetEventFreezeFrameData_GeneralEventInfo: start-on-event=GetEventFreezeFrameData, operation=GeneralEventInfo.GetEventFreezeFrameData
        OpEventGetEventFreezeFrameData_GetEventFreezeFrameData_EvtInfo_DTC_0xF00316: start-on-event=GetEventFreezeFrameData, operation=EvtInfo_DTC_0xF00316.GetEventFreezeFrameData
        OpEventGetEventFreezeFrameData_GetEventFreezeFrameData_Event_DTC_0xF00316: start-on-event=GetEventFreezeFrameData, operation=Event_DTC_0xF00316.GetEventFreezeFrameData
        OpEventGetEventFreezeFrameData_GetEventFreezeFrameData_EvtInfo_DTC_0xC19800: start-on-event=GetEventFreezeFrameData, operation=EvtInfo_DTC_0xC19800.GetEventFreezeFrameData
        OpEventGetEventFreezeFrameData_GetEventFreezeFrameData_Event_DTC_0xC19800: start-on-event=GetEventFreezeFrameData, operation=Event_DTC_0xC19800.GetEventFreezeFrameData
        OpEventGetEventFreezeFrameData_GetEventFreezeFrameData_EvtInfo_DTC_0xF00317: start-on-event=GetEventFreezeFrameData, operation=EvtInfo_DTC_0xF00317.GetEventFreezeFrameData
        OpEventGetEventFreezeFrameData_GetEventFreezeFrameData_Event_DTC_0xF00317: start-on-event=GetEventFreezeFrameData, operation=Event_DTC_0xF00317.GetEventFreezeFrameData
        OpEventGetEventFreezeFrameData_GetEventFreezeFrameData_EvtInfo_DTC_0xC14600: start-on-event=GetEventFreezeFrameData, operation=EvtInfo_DTC_0xC14600.GetEventFreezeFrameData
        OpEventGetEventFreezeFrameData_GetEventFreezeFrameData_Event_DTC_0xC14600: start-on-event=GetEventFreezeFrameData, operation=Event_DTC_0xC14600.GetEventFreezeFrameData
        OpEventGetEventFreezeFrameData_GetEventFreezeFrameData_EvtInfo_DTC_0xC18600: start-on-event=GetEventFreezeFrameData, operation=EvtInfo_DTC_0xC18600.GetEventFreezeFrameData
        OpEventGetEventFreezeFrameData_GetEventFreezeFrameData_Event_DTC_0xC18600: start-on-event=GetEventFreezeFrameData, operation=Event_DTC_0xC18600.GetEventFreezeFrameData
        OpEventGetEventFreezeFrameData_GetEventFreezeFrameData_EvtInfo_DTC_0xD96200: start-on-event=GetEventFreezeFrameData, operation=EvtInfo_DTC_0xD96200.GetEventFreezeFrameData
        OpEventGetEventFreezeFrameData_GetEventFreezeFrameData_Event_DTC_0xD96200: start-on-event=GetEventFreezeFrameData, operation=Event_DTC_0xD96200.GetEventFreezeFrameData
        OpEventGetEventFreezeFrameData_GetEventFreezeFrameData_EvtInfo_DTC_0xC18400: start-on-event=GetEventFreezeFrameData, operation=EvtInfo_DTC_0xC18400.GetEventFreezeFrameData
        OpEventGetEventFreezeFrameData_GetEventFreezeFrameData_Event_DTC_0xC18400: start-on-event=GetEventFreezeFrameData, operation=Event_DTC_0xC18400.GetEventFreezeFrameData
        OpEventGetEventFreezeFrameData_GetEventFreezeFrameData_EvtInfo_DTC_0xC15500: start-on-event=GetEventFreezeFrameData, operation=EvtInfo_DTC_0xC15500.GetEventFreezeFrameData
        OpEventGetEventFreezeFrameData_GetEventFreezeFrameData_Event_DTC_0xC15500: start-on-event=GetEventFreezeFrameData, operation=Event_DTC_0xC15500.GetEventFreezeFrameData
        OpEventGetEventFreezeFrameData_GetEventFreezeFrameData_EvtInfo_DTC_0xC07700: start-on-event=GetEventFreezeFrameData, operation=EvtInfo_DTC_0xC07700.GetEventFreezeFrameData
        OpEventGetEventFreezeFrameData_GetEventFreezeFrameData_Event_DTC_0xC07700: start-on-event=GetEventFreezeFrameData, operation=Event_DTC_0xC07700.GetEventFreezeFrameData
        OpEventGetEventFreezeFrameData_GetEventFreezeFrameData_EvtInfo_DTC_0xC16400: start-on-event=GetEventFreezeFrameData, operation=EvtInfo_DTC_0xC16400.GetEventFreezeFrameData
        OpEventGetEventFreezeFrameData_GetEventFreezeFrameData_Event_DTC_0xC16400: start-on-event=GetEventFreezeFrameData, operation=Event_DTC_0xC16400.GetEventFreezeFrameData
        OpEventGetEventFreezeFrameData_GetEventFreezeFrameData_EvtInfo_AutoCreatedDemEvent_CAN_5_PhysicalChannel_09246746_CANSM_7f66c965: start-on-event=GetEventFreezeFrameData, operation=EvtInfo_AutoCreatedDemEvent_CAN_5_PhysicalChannel_09246746_CANSM_E_BUS_OFF.GetEventFreezeFrameData
        OpEventGetEventFreezeFrameData_GetEventFreezeFrameData_EvtInfo_AutoCreatedDemEvent_EcuMConfiguration_ECUM_E_ALL_RUN_REQ_dff3eed8: start-on-event=GetEventFreezeFrameData, operation=EvtInfo_AutoCreatedDemEvent_EcuMConfiguration_ECUM_E_ALL_RUN_REQUESTS_KILLED.GetEventFreezeFrameData
        OpEventGetEventFreezeFrameData_GetEventFreezeFrameData_EvtInfo_AutoCreatedDemEvent_EcuMConfiguration_ECUM_E_CONFIGURATI_d69bc229: start-on-event=GetEventFreezeFrameData, operation=EvtInfo_AutoCreatedDemEvent_EcuMConfiguration_ECUM_E_CONFIGURATION_DATA_INCONSISTENT.GetEventFreezeFrameData
        OpEventGetEventFreezeFrameData_GetEventFreezeFrameData_EvtInfo_AutoCreatedDemEvent_EcuMConfiguration_ECUM_E_RAM_CHECK_FAILED: start-on-event=GetEventFreezeFrameData, operation=EvtInfo_AutoCreatedDemEvent_EcuMConfiguration_ECUM_E_RAM_CHECK_FAILED.GetEventFreezeFrameData
        OpEventGetEventFreezeFrameData_GetEventFreezeFrameData_EvtInfo_AutoCreatedDemEvent_EcuMConfiguration_ECUM_E_IMPROPER_CALLER: start-on-event=GetEventFreezeFrameData, operation=EvtInfo_AutoCreatedDemEvent_EcuMConfiguration_ECUM_E_IMPROPER_CALLER.GetEventFreezeFrameData
        OpEventGetEventFreezeFrameData_GetEventFreezeFrameData_EvtInfo_AutoCreatedDemEvent_NVM_E_INTEGRITY_FAILED: start-on-event=GetEventFreezeFrameData, operation=EvtInfo_AutoCreatedDemEvent_NVM_E_INTEGRITY_FAILED.GetEventFreezeFrameData
        OpEventGetEventFreezeFrameData_GetEventFreezeFrameData_EvtInfo_AutoCreatedDemEvent_NVM_E_LOSS_OF_REDUNDANCY: start-on-event=GetEventFreezeFrameData, operation=EvtInfo_AutoCreatedDemEvent_NVM_E_LOSS_OF_REDUNDANCY.GetEventFreezeFrameData
        OpEventGetEventFreezeFrameData_GetEventFreezeFrameData_EvtInfo_AutoCreatedDemEvent_NVM_E_QUEUE_OVERFLOW: start-on-event=GetEventFreezeFrameData, operation=EvtInfo_AutoCreatedDemEvent_NVM_E_QUEUE_OVERFLOW.GetEventFreezeFrameData
        OpEventGetEventFreezeFrameData_GetEventFreezeFrameData_EvtInfo_AutoCreatedDemEvent_NVM_E_REQ_FAILED: start-on-event=GetEventFreezeFrameData, operation=EvtInfo_AutoCreatedDemEvent_NVM_E_REQ_FAILED.GetEventFreezeFrameData
        OpEventGetEventFreezeFrameData_GetEventFreezeFrameData_EvtInfo_AutoCreatedDemEvent_NVM_E_VERIFY_FAILED: start-on-event=GetEventFreezeFrameData, operation=EvtInfo_AutoCreatedDemEvent_NVM_E_VERIFY_FAILED.GetEventFreezeFrameData
        OpEventGetEventFreezeFrameData_GetEventFreezeFrameData_EvtInfo_AutoCreatedDemEvent_NVM_E_WRITE_PROTECTED: start-on-event=GetEventFreezeFrameData, operation=EvtInfo_AutoCreatedDemEvent_NVM_E_WRITE_PROTECTED.GetEventFreezeFrameData
        OpEventGetEventFreezeFrameData_GetEventFreezeFrameData_EvtInfo_AutoCreatedDemEvent_NVM_E_WRONG_BLOCK_ID: start-on-event=GetEventFreezeFrameData, operation=EvtInfo_AutoCreatedDemEvent_NVM_E_WRONG_BLOCK_ID.GetEventFreezeFrameData
        OpEventGetEventFreezeFrameData_GetEventFreezeFrameData_EvtInfo_AutoCreatedDemEvent_WdgMConfigSet_WDGM_E_IMPROPER_CALLER: start-on-event=GetEventFreezeFrameData, operation=EvtInfo_AutoCreatedDemEvent_WdgMConfigSet_WDGM_E_IMPROPER_CALLER.GetEventFreezeFrameData
        OpEventGetEventFreezeFrameData_GetEventFreezeFrameData_EvtInfo_AutoCreatedDemEvent_WdgMConfigSet_WDGM_E_MONITORING: start-on-event=GetEventFreezeFrameData, operation=EvtInfo_AutoCreatedDemEvent_WdgMConfigSet_WDGM_E_MONITORING.GetEventFreezeFrameData
        OpEventGetEventFreezeFrameData_GetEventFreezeFrameData_EvtInfo_AutoCreatedDemEvent_WdgMConfigSet_WDGM_E_SET_MODE: start-on-event=GetEventFreezeFrameData, operation=EvtInfo_AutoCreatedDemEvent_WdgMConfigSet_WDGM_E_SET_MODE.GetEventFreezeFrameData
        OpEventGetEventFreezeFrameData_GetEventFreezeFrameData_EvtInfo_DemEventParameter_MCU_CLOCK_FAILURE: start-on-event=GetEventFreezeFrameData, operation=EvtInfo_DemEventParameter_MCU_CLOCK_FAILURE.GetEventFreezeFrameData
        OpEventGetEventFreezeFrameData_GetEventFreezeFrameData_EvtInfo_DemEventParameter_MCU_WRITE_TIMEOUT_FAILURE: start-on-event=GetEventFreezeFrameData, operation=EvtInfo_DemEventParameter_MCU_WRITE_TIMEOUT_FAILURE.GetEventFreezeFrameData
        OpEventGetEventFreezeFrameData_GetEventFreezeFrameData_EvtInfo_AutoCreatedDemEvent_FlsConfigSet_FLS_E_COMPARE_FAILED: start-on-event=GetEventFreezeFrameData, operation=EvtInfo_AutoCreatedDemEvent_FlsConfigSet_FLS_E_COMPARE_FAILED.GetEventFreezeFrameData
        OpEventGetEventFreezeFrameData_GetEventFreezeFrameData_EvtInfo_AutoCreatedDemEvent_FlsConfigSet_FLS_E_ERASE_FAILED: start-on-event=GetEventFreezeFrameData, operation=EvtInfo_AutoCreatedDemEvent_FlsConfigSet_FLS_E_ERASE_FAILED.GetEventFreezeFrameData
        OpEventGetEventFreezeFrameData_GetEventFreezeFrameData_EvtInfo_AutoCreatedDemEvent_FlsConfigSet_FLS_E_READ_FAILED: start-on-event=GetEventFreezeFrameData, operation=EvtInfo_AutoCreatedDemEvent_FlsConfigSet_FLS_E_READ_FAILED.GetEventFreezeFrameData
        OpEventGetEventFreezeFrameData_GetEventFreezeFrameData_EvtInfo_AutoCreatedDemEvent_FlsConfigSet_FLS_E_UNEXPECTED_FLASH_ID: start-on-event=GetEventFreezeFrameData, operation=EvtInfo_AutoCreatedDemEvent_FlsConfigSet_FLS_E_UNEXPECTED_FLASH_ID.GetEventFreezeFrameData
        OpEventGetEventFreezeFrameData_GetEventFreezeFrameData_EvtInfo_AutoCreatedDemEvent_FlsConfigSet_FLS_E_WRITE_FAILED: start-on-event=GetEventFreezeFrameData, operation=EvtInfo_AutoCreatedDemEvent_FlsConfigSet_FLS_E_WRITE_FAILED.GetEventFreezeFrameData
        OpEventGetEventFreezeFrameData_GetEventFreezeFrameData_EvtInfo_AutoCreatedDemEvent_WDG_E_DISABLE_REJECTED: start-on-event=GetEventFreezeFrameData, operation=EvtInfo_AutoCreatedDemEvent_WDG_E_DISABLE_REJECTED.GetEventFreezeFrameData
        OpEventGetEventFreezeFrameData_GetEventFreezeFrameData_EvtInfo_AutoCreatedDemEvent_WDG_E_MODE_FAILED: start-on-event=GetEventFreezeFrameData, operation=EvtInfo_AutoCreatedDemEvent_WDG_E_MODE_FAILED.GetEventFreezeFrameData
        OpEventGetEventFreezeFrameData_GetEventFreezeFrameData_EvtInfo_AutoCreatedDemEvent_FlsConfigSet_FLS_E_READ_FAILED_DED: start-on-event=GetEventFreezeFrameData, operation=EvtInfo_AutoCreatedDemEvent_FlsConfigSet_FLS_E_READ_FAILED_DED.GetEventFreezeFrameData
        OpEventGetEventFreezeFrameData_GetEventFreezeFrameData_EvtInfo_DemEventParameter_PORT_WRITE_TIMEOUT_FAILURE: start-on-event=GetEventFreezeFrameData, operation=EvtInfo_DemEventParameter_PORT_WRITE_TIMEOUT_FAILURE.GetEventFreezeFrameData
        OpEventGetEventFreezeFrameData_GetEventFreezeFrameData_EvtInfo_DemEventParameter_WDG_TRIGGER_TIMEOUT: start-on-event=GetEventFreezeFrameData, operation=EvtInfo_DemEventParameter_WDG_TRIGGER_TIMEOUT.GetEventFreezeFrameData
        OpEventGetEventFreezeFrameData_GetEventFreezeFrameData_EvtInfo_AutoCreatedDemEvent_SpiDriver_SPI_E_HARDWARE_ERROR: start-on-event=GetEventFreezeFrameData, operation=EvtInfo_AutoCreatedDemEvent_SpiDriver_SPI_E_HARDWARE_ERROR.GetEventFreezeFrameData
        OpEventGetEventFreezeFrameData_GetEventFreezeFrameData_EvtInfo_AutoCreatedDemEvent_SpiDriver_SPI_E_DATA_TX_TIMEOUT_FAILURE: start-on-event=GetEventFreezeFrameData, operation=EvtInfo_AutoCreatedDemEvent_SpiDriver_SPI_E_DATA_TX_TIMEOUT_FAILURE.GetEventFreezeFrameData
        OpEventGetEventFreezeFrameData_GetEventFreezeFrameData_EvtInfo_AutoCreatedDemEvent_CSM_E_INIT_FAILED: start-on-event=GetEventFreezeFrameData, operation=EvtInfo_AutoCreatedDemEvent_CSM_E_INIT_FAILED.GetEventFreezeFrameData
        OpEventGetEventFreezeFrameData_GetEventFreezeFrameData_EvtInfo_RAMTST_E_RAM_FAILURE: start-on-event=GetEventFreezeFrameData, operation=EvtInfo_RAMTST_E_RAM_FAILURE.GetEventFreezeFrameData
        OpEventGetEventFreezeFrameData_GetEventFreezeFrameData_EvtInfo_AutoCreatedDemEvent_WdgMConfigSet_WDGM_E_IMPROPER_CALLER_1: start-on-event=GetEventFreezeFrameData, operation=EvtInfo_AutoCreatedDemEvent_WdgMConfigSet_WDGM_E_IMPROPER_CALLER_1.GetEventFreezeFrameData
        OpEventGetEventFreezeFrameData_GetEventFreezeFrameData_EvtInfo_AutoCreatedDemEvent_WdgMConfigSet_WDGM_E_MONITORING_1: start-on-event=GetEventFreezeFrameData, operation=EvtInfo_AutoCreatedDemEvent_WdgMConfigSet_WDGM_E_MONITORING_1.GetEventFreezeFrameData
        OpEventGetEventFreezeFrameData_GetEventFreezeFrameData_EvtInfo_AutoCreatedDemEvent_WdgMConfigSet_WDGM_E_SET_MODE_1: start-on-event=GetEventFreezeFrameData, operation=EvtInfo_AutoCreatedDemEvent_WdgMConfigSet_WDGM_E_SET_MODE_1.GetEventFreezeFrameData
        OpEventGetEventFreezeFrameData_GetEventFreezeFrameData_EvtInfo_DemEventParameter_GPT_E_TIMEOUT: start-on-event=GetEventFreezeFrameData, operation=EvtInfo_DemEventParameter_GPT_E_TIMEOUT.GetEventFreezeFrameData
        OpEventGetEventFreezeFrameData_GetEventFreezeFrameData_Event_DemEventParameter_GPT_E_TIMEOUT: start-on-event=GetEventFreezeFrameData, operation=Event_DemEventParameter_GPT_E_TIMEOUT.GetEventFreezeFrameData
        OpEventGetEventExtendedDataRecord_GetEventExtendedDataRecord_GeneralEventInfo: start-on-event=GetEventExtendedDataRecord, operation=GeneralEventInfo.GetEventExtendedDataRecord
        OpEventGetEventExtendedDataRecord_GetEventExtendedDataRecord_EvtInfo_DTC_0xF00316: start-on-event=GetEventExtendedDataRecord, operation=EvtInfo_DTC_0xF00316.GetEventExtendedDataRecord
        OpEventGetEventExtendedDataRecord_GetEventExtendedDataRecord_Event_DTC_0xF00316: start-on-event=GetEventExtendedDataRecord, operation=Event_DTC_0xF00316.GetEventExtendedDataRecord
        OpEventGetEventExtendedDataRecord_GetEventExtendedDataRecord_EvtInfo_DTC_0xC19800: start-on-event=GetEventExtendedDataRecord, operation=EvtInfo_DTC_0xC19800.GetEventExtendedDataRecord
        OpEventGetEventExtendedDataRecord_GetEventExtendedDataRecord_Event_DTC_0xC19800: start-on-event=GetEventExtendedDataRecord, operation=Event_DTC_0xC19800.GetEventExtendedDataRecord
        OpEventGetEventExtendedDataRecord_GetEventExtendedDataRecord_EvtInfo_DTC_0xF00317: start-on-event=GetEventExtendedDataRecord, operation=EvtInfo_DTC_0xF00317.GetEventExtendedDataRecord
        OpEventGetEventExtendedDataRecord_GetEventExtendedDataRecord_Event_DTC_0xF00317: start-on-event=GetEventExtendedDataRecord, operation=Event_DTC_0xF00317.GetEventExtendedDataRecord
        OpEventGetEventExtendedDataRecord_GetEventExtendedDataRecord_EvtInfo_DTC_0xC14600: start-on-event=GetEventExtendedDataRecord, operation=EvtInfo_DTC_0xC14600.GetEventExtendedDataRecord
        OpEventGetEventExtendedDataRecord_GetEventExtendedDataRecord_Event_DTC_0xC14600: start-on-event=GetEventExtendedDataRecord, operation=Event_DTC_0xC14600.GetEventExtendedDataRecord
        OpEventGetEventExtendedDataRecord_GetEventExtendedDataRecord_EvtInfo_DTC_0xC18600: start-on-event=GetEventExtendedDataRecord, operation=EvtInfo_DTC_0xC18600.GetEventExtendedDataRecord
        OpEventGetEventExtendedDataRecord_GetEventExtendedDataRecord_Event_DTC_0xC18600: start-on-event=GetEventExtendedDataRecord, operation=Event_DTC_0xC18600.GetEventExtendedDataRecord
        OpEventGetEventExtendedDataRecord_GetEventExtendedDataRecord_EvtInfo_DTC_0xD96200: start-on-event=GetEventExtendedDataRecord, operation=EvtInfo_DTC_0xD96200.GetEventExtendedDataRecord
        OpEventGetEventExtendedDataRecord_GetEventExtendedDataRecord_Event_DTC_0xD96200: start-on-event=GetEventExtendedDataRecord, operation=Event_DTC_0xD96200.GetEventExtendedDataRecord
        OpEventGetEventExtendedDataRecord_GetEventExtendedDataRecord_EvtInfo_DTC_0xC18400: start-on-event=GetEventExtendedDataRecord, operation=EvtInfo_DTC_0xC18400.GetEventExtendedDataRecord
        OpEventGetEventExtendedDataRecord_GetEventExtendedDataRecord_Event_DTC_0xC18400: start-on-event=GetEventExtendedDataRecord, operation=Event_DTC_0xC18400.GetEventExtendedDataRecord
        OpEventGetEventExtendedDataRecord_GetEventExtendedDataRecord_EvtInfo_DTC_0xC15500: start-on-event=GetEventExtendedDataRecord, operation=EvtInfo_DTC_0xC15500.GetEventExtendedDataRecord
        OpEventGetEventExtendedDataRecord_GetEventExtendedDataRecord_Event_DTC_0xC15500: start-on-event=GetEventExtendedDataRecord, operation=Event_DTC_0xC15500.GetEventExtendedDataRecord
        OpEventGetEventExtendedDataRecord_GetEventExtendedDataRecord_EvtInfo_DTC_0xC07700: start-on-event=GetEventExtendedDataRecord, operation=EvtInfo_DTC_0xC07700.GetEventExtendedDataRecord
        OpEventGetEventExtendedDataRecord_GetEventExtendedDataRecord_Event_DTC_0xC07700: start-on-event=GetEventExtendedDataRecord, operation=Event_DTC_0xC07700.GetEventExtendedDataRecord
        OpEventGetEventExtendedDataRecord_GetEventExtendedDataRecord_EvtInfo_DTC_0xC16400: start-on-event=GetEventExtendedDataRecord, operation=EvtInfo_DTC_0xC16400.GetEventExtendedDataRecord
        OpEventGetEventExtendedDataRecord_GetEventExtendedDataRecord_Event_DTC_0xC16400: start-on-event=GetEventExtendedDataRecord, operation=Event_DTC_0xC16400.GetEventExtendedDataRecord
        OpEventGetEventExtendedDataRecord_GetEventExtendedDataRecord_EvtInfo_AutoCreatedDemEvent_CAN_5_PhysicalChannel_09246746_e5b1441b: start-on-event=GetEventExtendedDataRecord, operation=EvtInfo_AutoCreatedDemEvent_CAN_5_PhysicalChannel_09246746_CANSM_E_BUS_OFF.GetEventExtendedDataRecord
        OpEventGetEventExtendedDataRecord_GetEventExtendedDataRecord_EvtInfo_AutoCreatedDemEvent_EcuMConfiguration_ECUM_E_ALL_R_fd46dfea: start-on-event=GetEventExtendedDataRecord, operation=EvtInfo_AutoCreatedDemEvent_EcuMConfiguration_ECUM_E_ALL_RUN_REQUESTS_KILLED.GetEventExtendedDataRecord
        OpEventGetEventExtendedDataRecord_GetEventExtendedDataRecord_EvtInfo_AutoCreatedDemEvent_EcuMConfiguration_ECUM_E_CONFI_ee61c66d: start-on-event=GetEventExtendedDataRecord, operation=EvtInfo_AutoCreatedDemEvent_EcuMConfiguration_ECUM_E_CONFIGURATION_DATA_INCONSISTENT.GetEventExtendedDataRecord
        OpEventGetEventExtendedDataRecord_GetEventExtendedDataRecord_EvtInfo_AutoCreatedDemEvent_EcuMConfiguration_ECUM_E_RAM_C_3cc81dd0: start-on-event=GetEventExtendedDataRecord, operation=EvtInfo_AutoCreatedDemEvent_EcuMConfiguration_ECUM_E_RAM_CHECK_FAILED.GetEventExtendedDataRecord
        OpEventGetEventExtendedDataRecord_GetEventExtendedDataRecord_EvtInfo_AutoCreatedDemEvent_EcuMConfiguration_ECUM_E_IMPRO_6413fe6b: start-on-event=GetEventExtendedDataRecord, operation=EvtInfo_AutoCreatedDemEvent_EcuMConfiguration_ECUM_E_IMPROPER_CALLER.GetEventExtendedDataRecord
        OpEventGetEventExtendedDataRecord_GetEventExtendedDataRecord_EvtInfo_AutoCreatedDemEvent_NVM_E_INTEGRITY_FAILED: start-on-event=GetEventExtendedDataRecord, operation=EvtInfo_AutoCreatedDemEvent_NVM_E_INTEGRITY_FAILED.GetEventExtendedDataRecord
        OpEventGetEventExtendedDataRecord_GetEventExtendedDataRecord_EvtInfo_AutoCreatedDemEvent_NVM_E_LOSS_OF_REDUNDANCY: start-on-event=GetEventExtendedDataRecord, operation=EvtInfo_AutoCreatedDemEvent_NVM_E_LOSS_OF_REDUNDANCY.GetEventExtendedDataRecord
        OpEventGetEventExtendedDataRecord_GetEventExtendedDataRecord_EvtInfo_AutoCreatedDemEvent_NVM_E_QUEUE_OVERFLOW: start-on-event=GetEventExtendedDataRecord, operation=EvtInfo_AutoCreatedDemEvent_NVM_E_QUEUE_OVERFLOW.GetEventExtendedDataRecord
        OpEventGetEventExtendedDataRecord_GetEventExtendedDataRecord_EvtInfo_AutoCreatedDemEvent_NVM_E_REQ_FAILED: start-on-event=GetEventExtendedDataRecord, operation=EvtInfo_AutoCreatedDemEvent_NVM_E_REQ_FAILED.GetEventExtendedDataRecord
        OpEventGetEventExtendedDataRecord_GetEventExtendedDataRecord_EvtInfo_AutoCreatedDemEvent_NVM_E_VERIFY_FAILED: start-on-event=GetEventExtendedDataRecord, operation=EvtInfo_AutoCreatedDemEvent_NVM_E_VERIFY_FAILED.GetEventExtendedDataRecord
        OpEventGetEventExtendedDataRecord_GetEventExtendedDataRecord_EvtInfo_AutoCreatedDemEvent_NVM_E_WRITE_PROTECTED: start-on-event=GetEventExtendedDataRecord, operation=EvtInfo_AutoCreatedDemEvent_NVM_E_WRITE_PROTECTED.GetEventExtendedDataRecord
        OpEventGetEventExtendedDataRecord_GetEventExtendedDataRecord_EvtInfo_AutoCreatedDemEvent_NVM_E_WRONG_BLOCK_ID: start-on-event=GetEventExtendedDataRecord, operation=EvtInfo_AutoCreatedDemEvent_NVM_E_WRONG_BLOCK_ID.GetEventExtendedDataRecord
        OpEventGetEventExtendedDataRecord_GetEventExtendedDataRecord_EvtInfo_AutoCreatedDemEvent_WdgMConfigSet_WDGM_E_IMPROPER_CALLER: start-on-event=GetEventExtendedDataRecord, operation=EvtInfo_AutoCreatedDemEvent_WdgMConfigSet_WDGM_E_IMPROPER_CALLER.GetEventExtendedDataRecord
        OpEventGetEventExtendedDataRecord_GetEventExtendedDataRecord_EvtInfo_AutoCreatedDemEvent_WdgMConfigSet_WDGM_E_MONITORING: start-on-event=GetEventExtendedDataRecord, operation=EvtInfo_AutoCreatedDemEvent_WdgMConfigSet_WDGM_E_MONITORING.GetEventExtendedDataRecord
        OpEventGetEventExtendedDataRecord_GetEventExtendedDataRecord_EvtInfo_AutoCreatedDemEvent_WdgMConfigSet_WDGM_E_SET_MODE: start-on-event=GetEventExtendedDataRecord, operation=EvtInfo_AutoCreatedDemEvent_WdgMConfigSet_WDGM_E_SET_MODE.GetEventExtendedDataRecord
        OpEventGetEventExtendedDataRecord_GetEventExtendedDataRecord_EvtInfo_DemEventParameter_MCU_CLOCK_FAILURE: start-on-event=GetEventExtendedDataRecord, operation=EvtInfo_DemEventParameter_MCU_CLOCK_FAILURE.GetEventExtendedDataRecord
        OpEventGetEventExtendedDataRecord_GetEventExtendedDataRecord_EvtInfo_DemEventParameter_MCU_WRITE_TIMEOUT_FAILURE: start-on-event=GetEventExtendedDataRecord, operation=EvtInfo_DemEventParameter_MCU_WRITE_TIMEOUT_FAILURE.GetEventExtendedDataRecord
        OpEventGetEventExtendedDataRecord_GetEventExtendedDataRecord_EvtInfo_AutoCreatedDemEvent_FlsConfigSet_FLS_E_COMPARE_FAILED: start-on-event=GetEventExtendedDataRecord, operation=EvtInfo_AutoCreatedDemEvent_FlsConfigSet_FLS_E_COMPARE_FAILED.GetEventExtendedDataRecord
        OpEventGetEventExtendedDataRecord_GetEventExtendedDataRecord_EvtInfo_AutoCreatedDemEvent_FlsConfigSet_FLS_E_ERASE_FAILED: start-on-event=GetEventExtendedDataRecord, operation=EvtInfo_AutoCreatedDemEvent_FlsConfigSet_FLS_E_ERASE_FAILED.GetEventExtendedDataRecord
        OpEventGetEventExtendedDataRecord_GetEventExtendedDataRecord_EvtInfo_AutoCreatedDemEvent_FlsConfigSet_FLS_E_READ_FAILED: start-on-event=GetEventExtendedDataRecord, operation=EvtInfo_AutoCreatedDemEvent_FlsConfigSet_FLS_E_READ_FAILED.GetEventExtendedDataRecord
        OpEventGetEventExtendedDataRecord_GetEventExtendedDataRecord_EvtInfo_AutoCreatedDemEvent_FlsConfigSet_FLS_E_UNEXPECTED_FLASH_ID: start-on-event=GetEventExtendedDataRecord, operation=EvtInfo_AutoCreatedDemEvent_FlsConfigSet_FLS_E_UNEXPECTED_FLASH_ID.GetEventExtendedDataRecord
        OpEventGetEventExtendedDataRecord_GetEventExtendedDataRecord_EvtInfo_AutoCreatedDemEvent_FlsConfigSet_FLS_E_WRITE_FAILED: start-on-event=GetEventExtendedDataRecord, operation=EvtInfo_AutoCreatedDemEvent_FlsConfigSet_FLS_E_WRITE_FAILED.GetEventExtendedDataRecord
        OpEventGetEventExtendedDataRecord_GetEventExtendedDataRecord_EvtInfo_AutoCreatedDemEvent_WDG_E_DISABLE_REJECTED: start-on-event=GetEventExtendedDataRecord, operation=EvtInfo_AutoCreatedDemEvent_WDG_E_DISABLE_REJECTED.GetEventExtendedDataRecord
        OpEventGetEventExtendedDataRecord_GetEventExtendedDataRecord_EvtInfo_AutoCreatedDemEvent_WDG_E_MODE_FAILED: start-on-event=GetEventExtendedDataRecord, operation=EvtInfo_AutoCreatedDemEvent_WDG_E_MODE_FAILED.GetEventExtendedDataRecord
        OpEventGetEventExtendedDataRecord_GetEventExtendedDataRecord_EvtInfo_AutoCreatedDemEvent_FlsConfigSet_FLS_E_READ_FAILED_DED: start-on-event=GetEventExtendedDataRecord, operation=EvtInfo_AutoCreatedDemEvent_FlsConfigSet_FLS_E_READ_FAILED_DED.GetEventExtendedDataRecord
        OpEventGetEventExtendedDataRecord_GetEventExtendedDataRecord_EvtInfo_DemEventParameter_PORT_WRITE_TIMEOUT_FAILURE: start-on-event=GetEventExtendedDataRecord, operation=EvtInfo_DemEventParameter_PORT_WRITE_TIMEOUT_FAILURE.GetEventExtendedDataRecord
        OpEventGetEventExtendedDataRecord_GetEventExtendedDataRecord_EvtInfo_DemEventParameter_WDG_TRIGGER_TIMEOUT: start-on-event=GetEventExtendedDataRecord, operation=EvtInfo_DemEventParameter_WDG_TRIGGER_TIMEOUT.GetEventExtendedDataRecord
        OpEventGetEventExtendedDataRecord_GetEventExtendedDataRecord_EvtInfo_AutoCreatedDemEvent_SpiDriver_SPI_E_HARDWARE_ERROR: start-on-event=GetEventExtendedDataRecord, operation=EvtInfo_AutoCreatedDemEvent_SpiDriver_SPI_E_HARDWARE_ERROR.GetEventExtendedDataRecord
        OpEventGetEventExtendedDataRecord_GetEventExtendedDataRecord_EvtInfo_AutoCreatedDemEvent_SpiDriver_SPI_E_DATA_TX_TIMEOUT_FAILURE: start-on-event=GetEventExtendedDataRecord, operation=EvtInfo_AutoCreatedDemEvent_SpiDriver_SPI_E_DATA_TX_TIMEOUT_FAILURE.GetEventExtendedDataRecord
        OpEventGetEventExtendedDataRecord_GetEventExtendedDataRecord_EvtInfo_AutoCreatedDemEvent_CSM_E_INIT_FAILED: start-on-event=GetEventExtendedDataRecord, operation=EvtInfo_AutoCreatedDemEvent_CSM_E_INIT_FAILED.GetEventExtendedDataRecord
        OpEventGetEventExtendedDataRecord_GetEventExtendedDataRecord_EvtInfo_RAMTST_E_RAM_FAILURE: start-on-event=GetEventExtendedDataRecord, operation=EvtInfo_RAMTST_E_RAM_FAILURE.GetEventExtendedDataRecord
        OpEventGetEventExtendedDataRecord_GetEventExtendedDataRecord_EvtInfo_AutoCreatedDemEvent_WdgMConfigSet_WDGM_E_IMPROPER_CALLER_1: start-on-event=GetEventExtendedDataRecord, operation=EvtInfo_AutoCreatedDemEvent_WdgMConfigSet_WDGM_E_IMPROPER_CALLER_1.GetEventExtendedDataRecord
        OpEventGetEventExtendedDataRecord_GetEventExtendedDataRecord_EvtInfo_AutoCreatedDemEvent_WdgMConfigSet_WDGM_E_MONITORING_1: start-on-event=GetEventExtendedDataRecord, operation=EvtInfo_AutoCreatedDemEvent_WdgMConfigSet_WDGM_E_MONITORING_1.GetEventExtendedDataRecord
        OpEventGetEventExtendedDataRecord_GetEventExtendedDataRecord_EvtInfo_AutoCreatedDemEvent_WdgMConfigSet_WDGM_E_SET_MODE_1: start-on-event=GetEventExtendedDataRecord, operation=EvtInfo_AutoCreatedDemEvent_WdgMConfigSet_WDGM_E_SET_MODE_1.GetEventExtendedDataRecord
        OpEventGetEventExtendedDataRecord_GetEventExtendedDataRecord_EvtInfo_DemEventParameter_GPT_E_TIMEOUT: start-on-event=GetEventExtendedDataRecord, operation=EvtInfo_DemEventParameter_GPT_E_TIMEOUT.GetEventExtendedDataRecord
        OpEventGetEventExtendedDataRecord_GetEventExtendedDataRecord_Event_DemEventParameter_GPT_E_TIMEOUT: start-on-event=GetEventExtendedDataRecord, operation=Event_DemEventParameter_GPT_E_TIMEOUT.GetEventExtendedDataRecord
        OpEventGetEventEnableCondition_GetEventEnableCondition_GeneralEventInfo: start-on-event=GetEventEnableCondition, operation=GeneralEventInfo.GetEventEnableCondition
        OpEventGetEventEnableCondition_GetEventEnableCondition_EvtInfo_DTC_0xF00316: start-on-event=GetEventEnableCondition, operation=EvtInfo_DTC_0xF00316.GetEventEnableCondition
        OpEventGetEventEnableCondition_GetEventEnableCondition_EvtInfo_DTC_0xC19800: start-on-event=GetEventEnableCondition, operation=EvtInfo_DTC_0xC19800.GetEventEnableCondition
        OpEventGetEventEnableCondition_GetEventEnableCondition_EvtInfo_DTC_0xF00317: start-on-event=GetEventEnableCondition, operation=EvtInfo_DTC_0xF00317.GetEventEnableCondition
        OpEventGetEventEnableCondition_GetEventEnableCondition_EvtInfo_DTC_0xC14600: start-on-event=GetEventEnableCondition, operation=EvtInfo_DTC_0xC14600.GetEventEnableCondition
        OpEventGetEventEnableCondition_GetEventEnableCondition_EvtInfo_DTC_0xC18600: start-on-event=GetEventEnableCondition, operation=EvtInfo_DTC_0xC18600.GetEventEnableCondition
        OpEventGetEventEnableCondition_GetEventEnableCondition_EvtInfo_DTC_0xD96200: start-on-event=GetEventEnableCondition, operation=EvtInfo_DTC_0xD96200.GetEventEnableCondition
        OpEventGetEventEnableCondition_GetEventEnableCondition_EvtInfo_DTC_0xC18400: start-on-event=GetEventEnableCondition, operation=EvtInfo_DTC_0xC18400.GetEventEnableCondition
        OpEventGetEventEnableCondition_GetEventEnableCondition_EvtInfo_DTC_0xC15500: start-on-event=GetEventEnableCondition, operation=EvtInfo_DTC_0xC15500.GetEventEnableCondition
        OpEventGetEventEnableCondition_GetEventEnableCondition_EvtInfo_DTC_0xC07700: start-on-event=GetEventEnableCondition, operation=EvtInfo_DTC_0xC07700.GetEventEnableCondition
        OpEventGetEventEnableCondition_GetEventEnableCondition_EvtInfo_DTC_0xC16400: start-on-event=GetEventEnableCondition, operation=EvtInfo_DTC_0xC16400.GetEventEnableCondition
        OpEventGetEventEnableCondition_GetEventEnableCondition_EvtInfo_AutoCreatedDemEvent_CAN_5_PhysicalChannel_09246746_CANSM_38feecd6: start-on-event=GetEventEnableCondition, operation=EvtInfo_AutoCreatedDemEvent_CAN_5_PhysicalChannel_09246746_CANSM_E_BUS_OFF.GetEventEnableCondition
        OpEventGetEventEnableCondition_GetEventEnableCondition_EvtInfo_AutoCreatedDemEvent_EcuMConfiguration_ECUM_E_ALL_RUN_REQ_5b1f807c: start-on-event=GetEventEnableCondition, operation=EvtInfo_AutoCreatedDemEvent_EcuMConfiguration_ECUM_E_ALL_RUN_REQUESTS_KILLED.GetEventEnableCondition
        OpEventGetEventEnableCondition_GetEventEnableCondition_EvtInfo_AutoCreatedDemEvent_EcuMConfiguration_ECUM_E_CONFIGURATI_06f5d14c: start-on-event=GetEventEnableCondition, operation=EvtInfo_AutoCreatedDemEvent_EcuMConfiguration_ECUM_E_CONFIGURATION_DATA_INCONSISTENT.GetEventEnableCondition
        OpEventGetEventEnableCondition_GetEventEnableCondition_EvtInfo_AutoCreatedDemEvent_EcuMConfiguration_ECUM_E_RAM_CHECK_FAILED: start-on-event=GetEventEnableCondition, operation=EvtInfo_AutoCreatedDemEvent_EcuMConfiguration_ECUM_E_RAM_CHECK_FAILED.GetEventEnableCondition
        OpEventGetEventEnableCondition_GetEventEnableCondition_EvtInfo_AutoCreatedDemEvent_EcuMConfiguration_ECUM_E_IMPROPER_CALLER: start-on-event=GetEventEnableCondition, operation=EvtInfo_AutoCreatedDemEvent_EcuMConfiguration_ECUM_E_IMPROPER_CALLER.GetEventEnableCondition
        OpEventGetEventEnableCondition_GetEventEnableCondition_EvtInfo_AutoCreatedDemEvent_NVM_E_INTEGRITY_FAILED: start-on-event=GetEventEnableCondition, operation=EvtInfo_AutoCreatedDemEvent_NVM_E_INTEGRITY_FAILED.GetEventEnableCondition
        OpEventGetEventEnableCondition_GetEventEnableCondition_EvtInfo_AutoCreatedDemEvent_NVM_E_LOSS_OF_REDUNDANCY: start-on-event=GetEventEnableCondition, operation=EvtInfo_AutoCreatedDemEvent_NVM_E_LOSS_OF_REDUNDANCY.GetEventEnableCondition
        OpEventGetEventEnableCondition_GetEventEnableCondition_EvtInfo_AutoCreatedDemEvent_NVM_E_QUEUE_OVERFLOW: start-on-event=GetEventEnableCondition, operation=EvtInfo_AutoCreatedDemEvent_NVM_E_QUEUE_OVERFLOW.GetEventEnableCondition
        OpEventGetEventEnableCondition_GetEventEnableCondition_EvtInfo_AutoCreatedDemEvent_NVM_E_REQ_FAILED: start-on-event=GetEventEnableCondition, operation=EvtInfo_AutoCreatedDemEvent_NVM_E_REQ_FAILED.GetEventEnableCondition
        OpEventGetEventEnableCondition_GetEventEnableCondition_EvtInfo_AutoCreatedDemEvent_NVM_E_VERIFY_FAILED: start-on-event=GetEventEnableCondition, operation=EvtInfo_AutoCreatedDemEvent_NVM_E_VERIFY_FAILED.GetEventEnableCondition
        OpEventGetEventEnableCondition_GetEventEnableCondition_EvtInfo_AutoCreatedDemEvent_NVM_E_WRITE_PROTECTED: start-on-event=GetEventEnableCondition, operation=EvtInfo_AutoCreatedDemEvent_NVM_E_WRITE_PROTECTED.GetEventEnableCondition
        OpEventGetEventEnableCondition_GetEventEnableCondition_EvtInfo_AutoCreatedDemEvent_NVM_E_WRONG_BLOCK_ID: start-on-event=GetEventEnableCondition, operation=EvtInfo_AutoCreatedDemEvent_NVM_E_WRONG_BLOCK_ID.GetEventEnableCondition
        OpEventGetEventEnableCondition_GetEventEnableCondition_EvtInfo_AutoCreatedDemEvent_WdgMConfigSet_WDGM_E_IMPROPER_CALLER: start-on-event=GetEventEnableCondition, operation=EvtInfo_AutoCreatedDemEvent_WdgMConfigSet_WDGM_E_IMPROPER_CALLER.GetEventEnableCondition
        OpEventGetEventEnableCondition_GetEventEnableCondition_EvtInfo_AutoCreatedDemEvent_WdgMConfigSet_WDGM_E_MONITORING: start-on-event=GetEventEnableCondition, operation=EvtInfo_AutoCreatedDemEvent_WdgMConfigSet_WDGM_E_MONITORING.GetEventEnableCondition
        OpEventGetEventEnableCondition_GetEventEnableCondition_EvtInfo_AutoCreatedDemEvent_WdgMConfigSet_WDGM_E_SET_MODE: start-on-event=GetEventEnableCondition, operation=EvtInfo_AutoCreatedDemEvent_WdgMConfigSet_WDGM_E_SET_MODE.GetEventEnableCondition
        OpEventGetEventEnableCondition_GetEventEnableCondition_EvtInfo_DemEventParameter_MCU_CLOCK_FAILURE: start-on-event=GetEventEnableCondition, operation=EvtInfo_DemEventParameter_MCU_CLOCK_FAILURE.GetEventEnableCondition
        OpEventGetEventEnableCondition_GetEventEnableCondition_EvtInfo_DemEventParameter_MCU_WRITE_TIMEOUT_FAILURE: start-on-event=GetEventEnableCondition, operation=EvtInfo_DemEventParameter_MCU_WRITE_TIMEOUT_FAILURE.GetEventEnableCondition
        OpEventGetEventEnableCondition_GetEventEnableCondition_EvtInfo_AutoCreatedDemEvent_FlsConfigSet_FLS_E_COMPARE_FAILED: start-on-event=GetEventEnableCondition, operation=EvtInfo_AutoCreatedDemEvent_FlsConfigSet_FLS_E_COMPARE_FAILED.GetEventEnableCondition
        OpEventGetEventEnableCondition_GetEventEnableCondition_EvtInfo_AutoCreatedDemEvent_FlsConfigSet_FLS_E_ERASE_FAILED: start-on-event=GetEventEnableCondition, operation=EvtInfo_AutoCreatedDemEvent_FlsConfigSet_FLS_E_ERASE_FAILED.GetEventEnableCondition
        OpEventGetEventEnableCondition_GetEventEnableCondition_EvtInfo_AutoCreatedDemEvent_FlsConfigSet_FLS_E_READ_FAILED: start-on-event=GetEventEnableCondition, operation=EvtInfo_AutoCreatedDemEvent_FlsConfigSet_FLS_E_READ_FAILED.GetEventEnableCondition
        OpEventGetEventEnableCondition_GetEventEnableCondition_EvtInfo_AutoCreatedDemEvent_FlsConfigSet_FLS_E_UNEXPECTED_FLASH_ID: start-on-event=GetEventEnableCondition, operation=EvtInfo_AutoCreatedDemEvent_FlsConfigSet_FLS_E_UNEXPECTED_FLASH_ID.GetEventEnableCondition
        OpEventGetEventEnableCondition_GetEventEnableCondition_EvtInfo_AutoCreatedDemEvent_FlsConfigSet_FLS_E_WRITE_FAILED: start-on-event=GetEventEnableCondition, operation=EvtInfo_AutoCreatedDemEvent_FlsConfigSet_FLS_E_WRITE_FAILED.GetEventEnableCondition
        OpEventGetEventEnableCondition_GetEventEnableCondition_EvtInfo_AutoCreatedDemEvent_WDG_E_DISABLE_REJECTED: start-on-event=GetEventEnableCondition, operation=EvtInfo_AutoCreatedDemEvent_WDG_E_DISABLE_REJECTED.GetEventEnableCondition
        OpEventGetEventEnableCondition_GetEventEnableCondition_EvtInfo_AutoCreatedDemEvent_WDG_E_MODE_FAILED: start-on-event=GetEventEnableCondition, operation=EvtInfo_AutoCreatedDemEvent_WDG_E_MODE_FAILED.GetEventEnableCondition
        OpEventGetEventEnableCondition_GetEventEnableCondition_EvtInfo_AutoCreatedDemEvent_FlsConfigSet_FLS_E_READ_FAILED_DED: start-on-event=GetEventEnableCondition, operation=EvtInfo_AutoCreatedDemEvent_FlsConfigSet_FLS_E_READ_FAILED_DED.GetEventEnableCondition
        OpEventGetEventEnableCondition_GetEventEnableCondition_EvtInfo_DemEventParameter_PORT_WRITE_TIMEOUT_FAILURE: start-on-event=GetEventEnableCondition, operation=EvtInfo_DemEventParameter_PORT_WRITE_TIMEOUT_FAILURE.GetEventEnableCondition
        OpEventGetEventEnableCondition_GetEventEnableCondition_EvtInfo_DemEventParameter_WDG_TRIGGER_TIMEOUT: start-on-event=GetEventEnableCondition, operation=EvtInfo_DemEventParameter_WDG_TRIGGER_TIMEOUT.GetEventEnableCondition
        OpEventGetEventEnableCondition_GetEventEnableCondition_EvtInfo_AutoCreatedDemEvent_SpiDriver_SPI_E_HARDWARE_ERROR: start-on-event=GetEventEnableCondition, operation=EvtInfo_AutoCreatedDemEvent_SpiDriver_SPI_E_HARDWARE_ERROR.GetEventEnableCondition
        OpEventGetEventEnableCondition_GetEventEnableCondition_EvtInfo_AutoCreatedDemEvent_SpiDriver_SPI_E_DATA_TX_TIMEOUT_FAILURE: start-on-event=GetEventEnableCondition, operation=EvtInfo_AutoCreatedDemEvent_SpiDriver_SPI_E_DATA_TX_TIMEOUT_FAILURE.GetEventEnableCondition
        OpEventGetEventEnableCondition_GetEventEnableCondition_EvtInfo_AutoCreatedDemEvent_CSM_E_INIT_FAILED: start-on-event=GetEventEnableCondition, operation=EvtInfo_AutoCreatedDemEvent_CSM_E_INIT_FAILED.GetEventEnableCondition
        OpEventGetEventEnableCondition_GetEventEnableCondition_EvtInfo_RAMTST_E_RAM_FAILURE: start-on-event=GetEventEnableCondition, operation=EvtInfo_RAMTST_E_RAM_FAILURE.GetEventEnableCondition
        OpEventGetEventEnableCondition_GetEventEnableCondition_EvtInfo_AutoCreatedDemEvent_WdgMConfigSet_WDGM_E_IMPROPER_CALLER_1: start-on-event=GetEventEnableCondition, operation=EvtInfo_AutoCreatedDemEvent_WdgMConfigSet_WDGM_E_IMPROPER_CALLER_1.GetEventEnableCondition
        OpEventGetEventEnableCondition_GetEventEnableCondition_EvtInfo_AutoCreatedDemEvent_WdgMConfigSet_WDGM_E_MONITORING_1: start-on-event=GetEventEnableCondition, operation=EvtInfo_AutoCreatedDemEvent_WdgMConfigSet_WDGM_E_MONITORING_1.GetEventEnableCondition
        OpEventGetEventEnableCondition_GetEventEnableCondition_EvtInfo_AutoCreatedDemEvent_WdgMConfigSet_WDGM_E_SET_MODE_1: start-on-event=GetEventEnableCondition, operation=EvtInfo_AutoCreatedDemEvent_WdgMConfigSet_WDGM_E_SET_MODE_1.GetEventEnableCondition
        OpEventGetEventEnableCondition_GetEventEnableCondition_EvtInfo_DemEventParameter_GPT_E_TIMEOUT: start-on-event=GetEventEnableCondition, operation=EvtInfo_DemEventParameter_GPT_E_TIMEOUT.GetEventEnableCondition
        OpEventGetDebouncingOfEvent_GetDebouncingOfEvent_GeneralEventInfo: start-on-event=GetDebouncingOfEvent, operation=GeneralEventInfo.GetDebouncingOfEvent
        OpEventGetDebouncingOfEvent_GetDebouncingOfEvent_EvtInfo_DTC_0xF00316: start-on-event=GetDebouncingOfEvent, operation=EvtInfo_DTC_0xF00316.GetDebouncingOfEvent
        OpEventGetDebouncingOfEvent_GetDebouncingOfEvent_EvtInfo_DTC_0xC19800: start-on-event=GetDebouncingOfEvent, operation=EvtInfo_DTC_0xC19800.GetDebouncingOfEvent
        OpEventGetDebouncingOfEvent_GetDebouncingOfEvent_EvtInfo_DTC_0xF00317: start-on-event=GetDebouncingOfEvent, operation=EvtInfo_DTC_0xF00317.GetDebouncingOfEvent
        OpEventGetDebouncingOfEvent_GetDebouncingOfEvent_EvtInfo_DTC_0xC14600: start-on-event=GetDebouncingOfEvent, operation=EvtInfo_DTC_0xC14600.GetDebouncingOfEvent
        OpEventGetDebouncingOfEvent_GetDebouncingOfEvent_EvtInfo_DTC_0xC18600: start-on-event=GetDebouncingOfEvent, operation=EvtInfo_DTC_0xC18600.GetDebouncingOfEvent
        OpEventGetDebouncingOfEvent_GetDebouncingOfEvent_EvtInfo_DTC_0xD96200: start-on-event=GetDebouncingOfEvent, operation=EvtInfo_DTC_0xD96200.GetDebouncingOfEvent
        OpEventGetDebouncingOfEvent_GetDebouncingOfEvent_EvtInfo_DTC_0xC18400: start-on-event=GetDebouncingOfEvent, operation=EvtInfo_DTC_0xC18400.GetDebouncingOfEvent
        OpEventGetDebouncingOfEvent_GetDebouncingOfEvent_EvtInfo_DTC_0xC15500: start-on-event=GetDebouncingOfEvent, operation=EvtInfo_DTC_0xC15500.GetDebouncingOfEvent
        OpEventGetDebouncingOfEvent_GetDebouncingOfEvent_EvtInfo_DTC_0xC07700: start-on-event=GetDebouncingOfEvent, operation=EvtInfo_DTC_0xC07700.GetDebouncingOfEvent
        OpEventGetDebouncingOfEvent_GetDebouncingOfEvent_EvtInfo_DTC_0xC16400: start-on-event=GetDebouncingOfEvent, operation=EvtInfo_DTC_0xC16400.GetDebouncingOfEvent
        OpEventGetDebouncingOfEvent_GetDebouncingOfEvent_EvtInfo_AutoCreatedDemEvent_CAN_5_PhysicalChannel_09246746_CANSM_E_BUS_OFF: start-on-event=GetDebouncingOfEvent, operation=EvtInfo_AutoCreatedDemEvent_CAN_5_PhysicalChannel_09246746_CANSM_E_BUS_OFF.GetDebouncingOfEvent
        OpEventGetDebouncingOfEvent_GetDebouncingOfEvent_EvtInfo_AutoCreatedDemEvent_EcuMConfiguration_ECUM_E_ALL_RUN_REQUESTS_KILLED: start-on-event=GetDebouncingOfEvent, operation=EvtInfo_AutoCreatedDemEvent_EcuMConfiguration_ECUM_E_ALL_RUN_REQUESTS_KILLED.GetDebouncingOfEvent
        OpEventGetDebouncingOfEvent_GetDebouncingOfEvent_EvtInfo_AutoCreatedDemEvent_EcuMConfiguration_ECUM_E_CONFIGURATION_DAT_7642b2c3: start-on-event=GetDebouncingOfEvent, operation=EvtInfo_AutoCreatedDemEvent_EcuMConfiguration_ECUM_E_CONFIGURATION_DATA_INCONSISTENT.GetDebouncingOfEvent
        OpEventGetDebouncingOfEvent_GetDebouncingOfEvent_EvtInfo_AutoCreatedDemEvent_EcuMConfiguration_ECUM_E_RAM_CHECK_FAILED: start-on-event=GetDebouncingOfEvent, operation=EvtInfo_AutoCreatedDemEvent_EcuMConfiguration_ECUM_E_RAM_CHECK_FAILED.GetDebouncingOfEvent
        OpEventGetDebouncingOfEvent_GetDebouncingOfEvent_EvtInfo_AutoCreatedDemEvent_EcuMConfiguration_ECUM_E_IMPROPER_CALLER: start-on-event=GetDebouncingOfEvent, operation=EvtInfo_AutoCreatedDemEvent_EcuMConfiguration_ECUM_E_IMPROPER_CALLER.GetDebouncingOfEvent
        OpEventGetDebouncingOfEvent_GetDebouncingOfEvent_EvtInfo_AutoCreatedDemEvent_NVM_E_INTEGRITY_FAILED: start-on-event=GetDebouncingOfEvent, operation=EvtInfo_AutoCreatedDemEvent_NVM_E_INTEGRITY_FAILED.GetDebouncingOfEvent
        OpEventGetDebouncingOfEvent_GetDebouncingOfEvent_EvtInfo_AutoCreatedDemEvent_NVM_E_LOSS_OF_REDUNDANCY: start-on-event=GetDebouncingOfEvent, operation=EvtInfo_AutoCreatedDemEvent_NVM_E_LOSS_OF_REDUNDANCY.GetDebouncingOfEvent
        OpEventGetDebouncingOfEvent_GetDebouncingOfEvent_EvtInfo_AutoCreatedDemEvent_NVM_E_QUEUE_OVERFLOW: start-on-event=GetDebouncingOfEvent, operation=EvtInfo_AutoCreatedDemEvent_NVM_E_QUEUE_OVERFLOW.GetDebouncingOfEvent
        OpEventGetDebouncingOfEvent_GetDebouncingOfEvent_EvtInfo_AutoCreatedDemEvent_NVM_E_REQ_FAILED: start-on-event=GetDebouncingOfEvent, operation=EvtInfo_AutoCreatedDemEvent_NVM_E_REQ_FAILED.GetDebouncingOfEvent
        OpEventGetDebouncingOfEvent_GetDebouncingOfEvent_EvtInfo_AutoCreatedDemEvent_NVM_E_VERIFY_FAILED: start-on-event=GetDebouncingOfEvent, operation=EvtInfo_AutoCreatedDemEvent_NVM_E_VERIFY_FAILED.GetDebouncingOfEvent
        OpEventGetDebouncingOfEvent_GetDebouncingOfEvent_EvtInfo_AutoCreatedDemEvent_NVM_E_WRITE_PROTECTED: start-on-event=GetDebouncingOfEvent, operation=EvtInfo_AutoCreatedDemEvent_NVM_E_WRITE_PROTECTED.GetDebouncingOfEvent
        OpEventGetDebouncingOfEvent_GetDebouncingOfEvent_EvtInfo_AutoCreatedDemEvent_NVM_E_WRONG_BLOCK_ID: start-on-event=GetDebouncingOfEvent, operation=EvtInfo_AutoCreatedDemEvent_NVM_E_WRONG_BLOCK_ID.GetDebouncingOfEvent
        OpEventGetDebouncingOfEvent_GetDebouncingOfEvent_EvtInfo_AutoCreatedDemEvent_WdgMConfigSet_WDGM_E_IMPROPER_CALLER: start-on-event=GetDebouncingOfEvent, operation=EvtInfo_AutoCreatedDemEvent_WdgMConfigSet_WDGM_E_IMPROPER_CALLER.GetDebouncingOfEvent
        OpEventGetDebouncingOfEvent_GetDebouncingOfEvent_EvtInfo_AutoCreatedDemEvent_WdgMConfigSet_WDGM_E_MONITORING: start-on-event=GetDebouncingOfEvent, operation=EvtInfo_AutoCreatedDemEvent_WdgMConfigSet_WDGM_E_MONITORING.GetDebouncingOfEvent
        OpEventGetDebouncingOfEvent_GetDebouncingOfEvent_EvtInfo_AutoCreatedDemEvent_WdgMConfigSet_WDGM_E_SET_MODE: start-on-event=GetDebouncingOfEvent, operation=EvtInfo_AutoCreatedDemEvent_WdgMConfigSet_WDGM_E_SET_MODE.GetDebouncingOfEvent
        OpEventGetDebouncingOfEvent_GetDebouncingOfEvent_EvtInfo_DemEventParameter_MCU_CLOCK_FAILURE: start-on-event=GetDebouncingOfEvent, operation=EvtInfo_DemEventParameter_MCU_CLOCK_FAILURE.GetDebouncingOfEvent
        OpEventGetDebouncingOfEvent_GetDebouncingOfEvent_EvtInfo_DemEventParameter_MCU_WRITE_TIMEOUT_FAILURE: start-on-event=GetDebouncingOfEvent, operation=EvtInfo_DemEventParameter_MCU_WRITE_TIMEOUT_FAILURE.GetDebouncingOfEvent
        OpEventGetDebouncingOfEvent_GetDebouncingOfEvent_EvtInfo_AutoCreatedDemEvent_FlsConfigSet_FLS_E_COMPARE_FAILED: start-on-event=GetDebouncingOfEvent, operation=EvtInfo_AutoCreatedDemEvent_FlsConfigSet_FLS_E_COMPARE_FAILED.GetDebouncingOfEvent
        OpEventGetDebouncingOfEvent_GetDebouncingOfEvent_EvtInfo_AutoCreatedDemEvent_FlsConfigSet_FLS_E_ERASE_FAILED: start-on-event=GetDebouncingOfEvent, operation=EvtInfo_AutoCreatedDemEvent_FlsConfigSet_FLS_E_ERASE_FAILED.GetDebouncingOfEvent
        OpEventGetDebouncingOfEvent_GetDebouncingOfEvent_EvtInfo_AutoCreatedDemEvent_FlsConfigSet_FLS_E_READ_FAILED: start-on-event=GetDebouncingOfEvent, operation=EvtInfo_AutoCreatedDemEvent_FlsConfigSet_FLS_E_READ_FAILED.GetDebouncingOfEvent
        OpEventGetDebouncingOfEvent_GetDebouncingOfEvent_EvtInfo_AutoCreatedDemEvent_FlsConfigSet_FLS_E_UNEXPECTED_FLASH_ID: start-on-event=GetDebouncingOfEvent, operation=EvtInfo_AutoCreatedDemEvent_FlsConfigSet_FLS_E_UNEXPECTED_FLASH_ID.GetDebouncingOfEvent
        OpEventGetDebouncingOfEvent_GetDebouncingOfEvent_EvtInfo_AutoCreatedDemEvent_FlsConfigSet_FLS_E_WRITE_FAILED: start-on-event=GetDebouncingOfEvent, operation=EvtInfo_AutoCreatedDemEvent_FlsConfigSet_FLS_E_WRITE_FAILED.GetDebouncingOfEvent
        OpEventGetDebouncingOfEvent_GetDebouncingOfEvent_EvtInfo_AutoCreatedDemEvent_WDG_E_DISABLE_REJECTED: start-on-event=GetDebouncingOfEvent, operation=EvtInfo_AutoCreatedDemEvent_WDG_E_DISABLE_REJECTED.GetDebouncingOfEvent
        OpEventGetDebouncingOfEvent_GetDebouncingOfEvent_EvtInfo_AutoCreatedDemEvent_WDG_E_MODE_FAILED: start-on-event=GetDebouncingOfEvent, operation=EvtInfo_AutoCreatedDemEvent_WDG_E_MODE_FAILED.GetDebouncingOfEvent
        OpEventGetDebouncingOfEvent_GetDebouncingOfEvent_EvtInfo_AutoCreatedDemEvent_FlsConfigSet_FLS_E_READ_FAILED_DED: start-on-event=GetDebouncingOfEvent, operation=EvtInfo_AutoCreatedDemEvent_FlsConfigSet_FLS_E_READ_FAILED_DED.GetDebouncingOfEvent
        OpEventGetDebouncingOfEvent_GetDebouncingOfEvent_EvtInfo_DemEventParameter_PORT_WRITE_TIMEOUT_FAILURE: start-on-event=GetDebouncingOfEvent, operation=EvtInfo_DemEventParameter_PORT_WRITE_TIMEOUT_FAILURE.GetDebouncingOfEvent
        OpEventGetDebouncingOfEvent_GetDebouncingOfEvent_EvtInfo_DemEventParameter_WDG_TRIGGER_TIMEOUT: start-on-event=GetDebouncingOfEvent, operation=EvtInfo_DemEventParameter_WDG_TRIGGER_TIMEOUT.GetDebouncingOfEvent
        OpEventGetDebouncingOfEvent_GetDebouncingOfEvent_EvtInfo_AutoCreatedDemEvent_SpiDriver_SPI_E_HARDWARE_ERROR: start-on-event=GetDebouncingOfEvent, operation=EvtInfo_AutoCreatedDemEvent_SpiDriver_SPI_E_HARDWARE_ERROR.GetDebouncingOfEvent
        OpEventGetDebouncingOfEvent_GetDebouncingOfEvent_EvtInfo_AutoCreatedDemEvent_SpiDriver_SPI_E_DATA_TX_TIMEOUT_FAILURE: start-on-event=GetDebouncingOfEvent, operation=EvtInfo_AutoCreatedDemEvent_SpiDriver_SPI_E_DATA_TX_TIMEOUT_FAILURE.GetDebouncingOfEvent
        OpEventGetDebouncingOfEvent_GetDebouncingOfEvent_EvtInfo_AutoCreatedDemEvent_CSM_E_INIT_FAILED: start-on-event=GetDebouncingOfEvent, operation=EvtInfo_AutoCreatedDemEvent_CSM_E_INIT_FAILED.GetDebouncingOfEvent
        OpEventGetDebouncingOfEvent_GetDebouncingOfEvent_EvtInfo_RAMTST_E_RAM_FAILURE: start-on-event=GetDebouncingOfEvent, operation=EvtInfo_RAMTST_E_RAM_FAILURE.GetDebouncingOfEvent
        OpEventGetDebouncingOfEvent_GetDebouncingOfEvent_EvtInfo_AutoCreatedDemEvent_WdgMConfigSet_WDGM_E_IMPROPER_CALLER_1: start-on-event=GetDebouncingOfEvent, operation=EvtInfo_AutoCreatedDemEvent_WdgMConfigSet_WDGM_E_IMPROPER_CALLER_1.GetDebouncingOfEvent
        OpEventGetDebouncingOfEvent_GetDebouncingOfEvent_EvtInfo_AutoCreatedDemEvent_WdgMConfigSet_WDGM_E_MONITORING_1: start-on-event=GetDebouncingOfEvent, operation=EvtInfo_AutoCreatedDemEvent_WdgMConfigSet_WDGM_E_MONITORING_1.GetDebouncingOfEvent
        OpEventGetDebouncingOfEvent_GetDebouncingOfEvent_EvtInfo_AutoCreatedDemEvent_WdgMConfigSet_WDGM_E_SET_MODE_1: start-on-event=GetDebouncingOfEvent, operation=EvtInfo_AutoCreatedDemEvent_WdgMConfigSet_WDGM_E_SET_MODE_1.GetDebouncingOfEvent
        OpEventGetDebouncingOfEvent_GetDebouncingOfEvent_EvtInfo_DemEventParameter_GPT_E_TIMEOUT: start-on-event=GetDebouncingOfEvent, operation=EvtInfo_DemEventParameter_GPT_E_TIMEOUT.GetDebouncingOfEvent
        OpEventSetEventStatus_SetEventStatus_Event_DTC_0xF00316: start-on-event=SetEventStatus, operation=Event_DTC_0xF00316.SetEventStatus
        OpEventSetEventStatus_SetEventStatus_Event_DTC_0xC19800: start-on-event=SetEventStatus, operation=Event_DTC_0xC19800.SetEventStatus
        OpEventSetEventStatus_SetEventStatus_Event_DTC_0xF00317: start-on-event=SetEventStatus, operation=Event_DTC_0xF00317.SetEventStatus
        OpEventSetEventStatus_SetEventStatus_Event_DTC_0xC14600: start-on-event=SetEventStatus, operation=Event_DTC_0xC14600.SetEventStatus
        OpEventSetEventStatus_SetEventStatus_Event_DTC_0xC18600: start-on-event=SetEventStatus, operation=Event_DTC_0xC18600.SetEventStatus
        OpEventSetEventStatus_SetEventStatus_Event_DTC_0xD96200: start-on-event=SetEventStatus, operation=Event_DTC_0xD96200.SetEventStatus
        OpEventSetEventStatus_SetEventStatus_Event_DTC_0xC18400: start-on-event=SetEventStatus, operation=Event_DTC_0xC18400.SetEventStatus
        OpEventSetEventStatus_SetEventStatus_Event_DTC_0xC15500: start-on-event=SetEventStatus, operation=Event_DTC_0xC15500.SetEventStatus
        OpEventSetEventStatus_SetEventStatus_Event_DTC_0xC07700: start-on-event=SetEventStatus, operation=Event_DTC_0xC07700.SetEventStatus
        OpEventSetEventStatus_SetEventStatus_Event_DTC_0xC16400: start-on-event=SetEventStatus, operation=Event_DTC_0xC16400.SetEventStatus
        OpEventSetEventStatus_SetEventStatus_Event_DemEventParameter_GPT_E_TIMEOUT: start-on-event=SetEventStatus, operation=Event_DemEventParameter_GPT_E_TIMEOUT.SetEventStatus
        OpEventResetEventStatus_ResetEventStatus_Event_DTC_0xF00316: start-on-event=ResetEventStatus, operation=Event_DTC_0xF00316.ResetEventStatus
        OpEventResetEventStatus_ResetEventStatus_Event_DTC_0xC19800: start-on-event=ResetEventStatus, operation=Event_DTC_0xC19800.ResetEventStatus
        OpEventResetEventStatus_ResetEventStatus_Event_DTC_0xF00317: start-on-event=ResetEventStatus, operation=Event_DTC_0xF00317.ResetEventStatus
        OpEventResetEventStatus_ResetEventStatus_Event_DTC_0xC14600: start-on-event=ResetEventStatus, operation=Event_DTC_0xC14600.ResetEventStatus
        OpEventResetEventStatus_ResetEventStatus_Event_DTC_0xC18600: start-on-event=ResetEventStatus, operation=Event_DTC_0xC18600.ResetEventStatus
        OpEventResetEventStatus_ResetEventStatus_Event_DTC_0xD96200: start-on-event=ResetEventStatus, operation=Event_DTC_0xD96200.ResetEventStatus
        OpEventResetEventStatus_ResetEventStatus_Event_DTC_0xC18400: start-on-event=ResetEventStatus, operation=Event_DTC_0xC18400.ResetEventStatus
        OpEventResetEventStatus_ResetEventStatus_Event_DTC_0xC15500: start-on-event=ResetEventStatus, operation=Event_DTC_0xC15500.ResetEventStatus
        OpEventResetEventStatus_ResetEventStatus_Event_DTC_0xC07700: start-on-event=ResetEventStatus, operation=Event_DTC_0xC07700.ResetEventStatus
        OpEventResetEventStatus_ResetEventStatus_Event_DTC_0xC16400: start-on-event=ResetEventStatus, operation=Event_DTC_0xC16400.ResetEventStatus
        OpEventResetEventStatus_ResetEventStatus_Event_DemEventParameter_GPT_E_TIMEOUT: start-on-event=ResetEventStatus, operation=Event_DemEventParameter_GPT_E_TIMEOUT.ResetEventStatus
        OpEventResetEventDebounceStatus_ResetEventDebounceStatus_Event_DTC_0xF00316: start-on-event=ResetEventDebounceStatus, operation=Event_DTC_0xF00316.ResetEventDebounceStatus
        OpEventResetEventDebounceStatus_ResetEventDebounceStatus_Event_DTC_0xC19800: start-on-event=ResetEventDebounceStatus, operation=Event_DTC_0xC19800.ResetEventDebounceStatus
        OpEventResetEventDebounceStatus_ResetEventDebounceStatus_Event_DTC_0xF00317: start-on-event=ResetEventDebounceStatus, operation=Event_DTC_0xF00317.ResetEventDebounceStatus
        OpEventResetEventDebounceStatus_ResetEventDebounceStatus_Event_DTC_0xC14600: start-on-event=ResetEventDebounceStatus, operation=Event_DTC_0xC14600.ResetEventDebounceStatus
        OpEventResetEventDebounceStatus_ResetEventDebounceStatus_Event_DTC_0xC18600: start-on-event=ResetEventDebounceStatus, operation=Event_DTC_0xC18600.ResetEventDebounceStatus
        OpEventResetEventDebounceStatus_ResetEventDebounceStatus_Event_DTC_0xD96200: start-on-event=ResetEventDebounceStatus, operation=Event_DTC_0xD96200.ResetEventDebounceStatus
        OpEventResetEventDebounceStatus_ResetEventDebounceStatus_Event_DTC_0xC18400: start-on-event=ResetEventDebounceStatus, operation=Event_DTC_0xC18400.ResetEventDebounceStatus
        OpEventResetEventDebounceStatus_ResetEventDebounceStatus_Event_DTC_0xC15500: start-on-event=ResetEventDebounceStatus, operation=Event_DTC_0xC15500.ResetEventDebounceStatus
        OpEventResetEventDebounceStatus_ResetEventDebounceStatus_Event_DTC_0xC07700: start-on-event=ResetEventDebounceStatus, operation=Event_DTC_0xC07700.ResetEventDebounceStatus
        OpEventResetEventDebounceStatus_ResetEventDebounceStatus_Event_DTC_0xC16400: start-on-event=ResetEventDebounceStatus, operation=Event_DTC_0xC16400.ResetEventDebounceStatus
        OpEventResetEventDebounceStatus_ResetEventDebounceStatus_Event_DemEventParameter_GPT_E_TIMEOUT: start-on-event=ResetEventDebounceStatus, operation=Event_DemEventParameter_GPT_E_TIMEOUT.ResetEventDebounceStatus
        OpEventDcmClearDTC_DcmClearDTC_Dcm: start-on-event=DcmClearDTC, operation=Dcm.DcmClearDTC
        OpEventDcmGetNextFilteredDTCAndFDC_DcmGetNextFilteredDTCAndFDC_Dcm: start-on-event=DcmGetNextFilteredDTCAndFDC, operation=Dcm.DcmGetNextFilteredDTCAndFDC
        OpEventDcmEnableDTCSetting_DcmEnableDTCSetting_Dcm: start-on-event=DcmEnableDTCSetting, operation=Dcm.DcmEnableDTCSetting
        OpEventDcmGetFreezeFrameDataByDTC_DcmGetFreezeFrameDataByDTC_Dcm: start-on-event=DcmGetFreezeFrameDataByDTC, operation=Dcm.DcmGetFreezeFrameDataByDTC
        OpEventDcmGetExtendedDataRecordByDTC_DcmGetExtendedDataRecordByDTC_Dcm: start-on-event=DcmGetExtendedDataRecordByDTC, operation=Dcm.DcmGetExtendedDataRecordByDTC
        OpEventSetOperationCycleState_SetOperationCycleState_OpCycle_IgnitionCycle: start-on-event=SetOperationCycleState, operation=OpCycle_IgnitionCycle.SetOperationCycleState
        OpEventSetOperationCycleState_SetOperationCycleState_OpCycle_PowerCycle: start-on-event=SetOperationCycleState, operation=OpCycle_PowerCycle.SetOperationCycleState
      port-api-options:
        enable-take-address=true, indirect-api=false, port=Cdd
        enable-take-address=true, indirect-api=false, port=DemServices
        {enable-take-address=true, indirect-api=false, port-defined-argument-value{value=1, value-type=Dem_DTCOriginType}, port=OverflowIndPrimaryMemory}
        enable-take-address=true, indirect-api=false, port=GeneralEventInfo
        {enable-take-address=true, indirect-api=false, port-defined-argument-value{value=9, value-type=Dem_EventIdType}, port=EvtInfo_DTC_0xF00316}
        {enable-take-address=true, indirect-api=false, port-defined-argument-value{value=9, value-type=Dem_EventIdType}, port=Event_DTC_0xF00316}
        {enable-take-address=true, indirect-api=false, port-defined-argument-value{value=7, value-type=Dem_EventIdType}, port=EvtInfo_DTC_0xC19800}
        {enable-take-address=true, indirect-api=false, port-defined-argument-value{value=7, value-type=Dem_EventIdType}, port=Event_DTC_0xC19800}
        {enable-take-address=true, indirect-api=false, port-defined-argument-value{value=10, value-type=Dem_EventIdType}, port=EvtInfo_DTC_0xF00317}
        {enable-take-address=true, indirect-api=false, port-defined-argument-value{value=10, value-type=Dem_EventIdType}, port=Event_DTC_0xF00317}
        {enable-take-address=true, indirect-api=false, port-defined-argument-value{value=2, value-type=Dem_EventIdType}, port=EvtInfo_DTC_0xC14600}
        {enable-take-address=true, indirect-api=false, port-defined-argument-value{value=2, value-type=Dem_EventIdType}, port=Event_DTC_0xC14600}
        {enable-take-address=true, indirect-api=false, port-defined-argument-value{value=6, value-type=Dem_EventIdType}, port=EvtInfo_DTC_0xC18600}
        {enable-take-address=true, indirect-api=false, port-defined-argument-value{value=6, value-type=Dem_EventIdType}, port=Event_DTC_0xC18600}
        {enable-take-address=true, indirect-api=false, port-defined-argument-value{value=8, value-type=Dem_EventIdType}, port=EvtInfo_DTC_0xD96200}
        {enable-take-address=true, indirect-api=false, port-defined-argument-value{value=8, value-type=Dem_EventIdType}, port=Event_DTC_0xD96200}
        {enable-take-address=true, indirect-api=false, port-defined-argument-value{value=5, value-type=Dem_EventIdType}, port=EvtInfo_DTC_0xC18400}
        {enable-take-address=true, indirect-api=false, port-defined-argument-value{value=5, value-type=Dem_EventIdType}, port=Event_DTC_0xC18400}
        {enable-take-address=true, indirect-api=false, port-defined-argument-value{value=3, value-type=Dem_EventIdType}, port=EvtInfo_DTC_0xC15500}
        {enable-take-address=true, indirect-api=false, port-defined-argument-value{value=3, value-type=Dem_EventIdType}, port=Event_DTC_0xC15500}
        {enable-take-address=true, indirect-api=false, port-defined-argument-value{value=1, value-type=Dem_EventIdType}, port=EvtInfo_DTC_0xC07700}
        {enable-take-address=true, indirect-api=false, port-defined-argument-value{value=1, value-type=Dem_EventIdType}, port=Event_DTC_0xC07700}
        {enable-take-address=true, indirect-api=false, port-defined-argument-value{value=4, value-type=Dem_EventIdType}, port=EvtInfo_DTC_0xC16400}
        {enable-take-address=true, indirect-api=false, port-defined-argument-value{value=4, value-type=Dem_EventIdType}, port=Event_DTC_0xC16400}
        {enable-take-address=true, indirect-api=false, port-defined-argument-value{value=11, value-type=Dem_EventIdType}, port=EvtInfo_AutoCreatedDemEvent_CAN_5_PhysicalChannel_09246746_CANSM_E_BUS_OFF}
        {enable-take-address=true, indirect-api=false, port-defined-argument-value{value=12, value-type=Dem_EventIdType}, port=EvtInfo_AutoCreatedDemEvent_EcuMConfiguration_ECUM_E_ALL_RUN_REQUESTS_KILLED}
        {enable-take-address=true, indirect-api=false, port-defined-argument-value{value=13, value-type=Dem_EventIdType}, port=EvtInfo_AutoCreatedDemEvent_EcuMConfiguration_ECUM_E_CONFIGURATION_DATA_INCONSISTENT}
        {enable-take-address=true, indirect-api=false, port-defined-argument-value{value=15, value-type=Dem_EventIdType}, port=EvtInfo_AutoCreatedDemEvent_EcuMConfiguration_ECUM_E_RAM_CHECK_FAILED}
        {enable-take-address=true, indirect-api=false, port-defined-argument-value{value=14, value-type=Dem_EventIdType}, port=EvtInfo_AutoCreatedDemEvent_EcuMConfiguration_ECUM_E_IMPROPER_CALLER}
        {enable-take-address=true, indirect-api=false, port-defined-argument-value{value=16, value-type=Dem_EventIdType}, port=EvtInfo_AutoCreatedDemEvent_NVM_E_INTEGRITY_FAILED}
        {enable-take-address=true, indirect-api=false, port-defined-argument-value{value=17, value-type=Dem_EventIdType}, port=EvtInfo_AutoCreatedDemEvent_NVM_E_LOSS_OF_REDUNDANCY}
        {enable-take-address=true, indirect-api=false, port-defined-argument-value{value=18, value-type=Dem_EventIdType}, port=EvtInfo_AutoCreatedDemEvent_NVM_E_QUEUE_OVERFLOW}
        {enable-take-address=true, indirect-api=false, port-defined-argument-value{value=19, value-type=Dem_EventIdType}, port=EvtInfo_AutoCreatedDemEvent_NVM_E_REQ_FAILED}
        {enable-take-address=true, indirect-api=false, port-defined-argument-value{value=20, value-type=Dem_EventIdType}, port=EvtInfo_AutoCreatedDemEvent_NVM_E_VERIFY_FAILED}
        {enable-take-address=true, indirect-api=false, port-defined-argument-value{value=21, value-type=Dem_EventIdType}, port=EvtInfo_AutoCreatedDemEvent_NVM_E_WRITE_PROTECTED}
        {enable-take-address=true, indirect-api=false, port-defined-argument-value{value=22, value-type=Dem_EventIdType}, port=EvtInfo_AutoCreatedDemEvent_NVM_E_WRONG_BLOCK_ID}
        {enable-take-address=true, indirect-api=false, port-defined-argument-value{value=23, value-type=Dem_EventIdType}, port=EvtInfo_AutoCreatedDemEvent_WdgMConfigSet_WDGM_E_IMPROPER_CALLER}
        {enable-take-address=true, indirect-api=false, port-defined-argument-value{value=24, value-type=Dem_EventIdType}, port=EvtInfo_AutoCreatedDemEvent_WdgMConfigSet_WDGM_E_MONITORING}
        {enable-take-address=true, indirect-api=false, port-defined-argument-value{value=25, value-type=Dem_EventIdType}, port=EvtInfo_AutoCreatedDemEvent_WdgMConfigSet_WDGM_E_SET_MODE}
        {enable-take-address=true, indirect-api=false, port-defined-argument-value{value=26, value-type=Dem_EventIdType}, port=EvtInfo_DemEventParameter_MCU_CLOCK_FAILURE}
        {enable-take-address=true, indirect-api=false, port-defined-argument-value{value=27, value-type=Dem_EventIdType}, port=EvtInfo_DemEventParameter_MCU_WRITE_TIMEOUT_FAILURE}
        {enable-take-address=true, indirect-api=false, port-defined-argument-value{value=30, value-type=Dem_EventIdType}, port=EvtInfo_AutoCreatedDemEvent_FlsConfigSet_FLS_E_COMPARE_FAILED}
        {enable-take-address=true, indirect-api=false, port-defined-argument-value{value=31, value-type=Dem_EventIdType}, port=EvtInfo_AutoCreatedDemEvent_FlsConfigSet_FLS_E_ERASE_FAILED}
        {enable-take-address=true, indirect-api=false, port-defined-argument-value{value=32, value-type=Dem_EventIdType}, port=EvtInfo_AutoCreatedDemEvent_FlsConfigSet_FLS_E_READ_FAILED}
        {enable-take-address=true, indirect-api=false, port-defined-argument-value{value=34, value-type=Dem_EventIdType}, port=EvtInfo_AutoCreatedDemEvent_FlsConfigSet_FLS_E_UNEXPECTED_FLASH_ID}
        {enable-take-address=true, indirect-api=false, port-defined-argument-value{value=35, value-type=Dem_EventIdType}, port=EvtInfo_AutoCreatedDemEvent_FlsConfigSet_FLS_E_WRITE_FAILED}
        {enable-take-address=true, indirect-api=false, port-defined-argument-value{value=36, value-type=Dem_EventIdType}, port=EvtInfo_AutoCreatedDemEvent_WDG_E_DISABLE_REJECTED}
        {enable-take-address=true, indirect-api=false, port-defined-argument-value{value=37, value-type=Dem_EventIdType}, port=EvtInfo_AutoCreatedDemEvent_WDG_E_MODE_FAILED}
        {enable-take-address=true, indirect-api=false, port-defined-argument-value{value=33, value-type=Dem_EventIdType}, port=EvtInfo_AutoCreatedDemEvent_FlsConfigSet_FLS_E_READ_FAILED_DED}
        {enable-take-address=true, indirect-api=false, port-defined-argument-value{value=28, value-type=Dem_EventIdType}, port=EvtInfo_DemEventParameter_PORT_WRITE_TIMEOUT_FAILURE}
        {enable-take-address=true, indirect-api=false, port-defined-argument-value{value=29, value-type=Dem_EventIdType}, port=EvtInfo_DemEventParameter_WDG_TRIGGER_TIMEOUT}
        {enable-take-address=true, indirect-api=false, port-defined-argument-value{value=39, value-type=Dem_EventIdType}, port=EvtInfo_AutoCreatedDemEvent_SpiDriver_SPI_E_HARDWARE_ERROR}
        {enable-take-address=true, indirect-api=false, port-defined-argument-value{value=38, value-type=Dem_EventIdType}, port=EvtInfo_AutoCreatedDemEvent_SpiDriver_SPI_E_DATA_TX_TIMEOUT_FAILURE}
        {enable-take-address=true, indirect-api=false, port-defined-argument-value{value=40, value-type=Dem_EventIdType}, port=EvtInfo_AutoCreatedDemEvent_CSM_E_INIT_FAILED}
        {enable-take-address=true, indirect-api=false, port-defined-argument-value{value=41, value-type=Dem_EventIdType}, port=EvtInfo_RAMTST_E_RAM_FAILURE}
        {enable-take-address=true, indirect-api=false, port-defined-argument-value{value=42, value-type=Dem_EventIdType}, port=EvtInfo_AutoCreatedDemEvent_WdgMConfigSet_WDGM_E_IMPROPER_CALLER_1}
        {enable-take-address=true, indirect-api=false, port-defined-argument-value{value=43, value-type=Dem_EventIdType}, port=EvtInfo_AutoCreatedDemEvent_WdgMConfigSet_WDGM_E_MONITORING_1}
        {enable-take-address=true, indirect-api=false, port-defined-argument-value{value=44, value-type=Dem_EventIdType}, port=EvtInfo_AutoCreatedDemEvent_WdgMConfigSet_WDGM_E_SET_MODE_1}
        {enable-take-address=true, indirect-api=false, port-defined-argument-value{value=45, value-type=Dem_EventIdType}, port=EvtInfo_DemEventParameter_GPT_E_TIMEOUT}
        {enable-take-address=true, indirect-api=false, port-defined-argument-value{value=45, value-type=Dem_EventIdType}, port=Event_DemEventParameter_GPT_E_TIMEOUT}
        enable-take-address=true, indirect-api=false, port=Dcm
        {enable-take-address=true, indirect-api=false, port-defined-argument-value{value=0, value-type=Dem_OperationCycleIdType}, port=OpCycle_IgnitionCycle}
        {enable-take-address=true, indirect-api=false, port-defined-argument-value{value=1, value-type=Dem_OperationCycleIdType}, port=OpCycle_PowerCycle}
        enable-take-address=true, indirect-api=false, port=CBReadData_DID_0_Unknown_1
        enable-take-address=true, indirect-api=false, port=CBReadData_DID_0x1_Unknown_1
        enable-take-address=true, indirect-api=false, port=CBReadData_ExtendedDataRecord1_Unknown_1
      24 x runnable:
        Dem_MainFunction
          sync call OpServerCallDem_MainFunction_ReadData_CBReadData_DID_0_Unknown_1: operation=CBReadData_DID_0_Unknown_1.ReadData, timeout=0
          sync call OpServerCallDem_MainFunction_ReadData_CBReadData_DID_0x1_Unknown_1: operation=CBReadData_DID_0x1_Unknown_1.ReadData, timeout=0
          sync call OpServerCallDem_MainFunction_ReadData_CBReadData_ExtendedDataRecord1_Unknown_1: operation=CBReadData_ExtendedDataRecord1_Unknown_1.ReadData, timeout=0
        ClearDTC: can-be-invoked-concurrently=true, symbol=Dem_ClearDTC
        PostRunRequested: can-be-invoked-concurrently=true, symbol=Dem_PostRunRequested
        GetDTCStatusAvailabilityMask: can-be-invoked-concurrently=true, symbol=Dem_DcmGetDTCStatusAvailabilityMask
        GetEventMemoryOverflow: can-be-invoked-concurrently=true, symbol=Dem_GetEventMemoryOverflow
        GetNumberOfEventMemoryEntries: can-be-invoked-concurrently=true, symbol=Dem_GetNumberOfEventMemoryEntries
        GetEventStatus: can-be-invoked-concurrently=true, symbol=Dem_GetEventStatus
        GetEventFailed: can-be-invoked-concurrently=true, symbol=Dem_GetEventFailed
        GetEventTested: can-be-invoked-concurrently=true, symbol=Dem_GetEventTested
        GetDTCOfEvent: can-be-invoked-concurrently=true, symbol=Dem_GetDTCOfEvent
        GetFaultDetectionCounter: can-be-invoked-concurrently=true, symbol=Dem_GetFaultDetectionCounter
        GetEventFreezeFrameData: can-be-invoked-concurrently=true, symbol=Dem_GetEventFreezeFrameData
        GetEventExtendedDataRecord: can-be-invoked-concurrently=true, symbol=Dem_GetEventExtendedDataRecord
        GetEventEnableCondition: can-be-invoked-concurrently=true, symbol=Dem_GetEventEnableCondition
        GetDebouncingOfEvent: can-be-invoked-concurrently=true, symbol=Dem_GetDebouncingOfEvent
        SetEventStatus: can-be-invoked-concurrently=true, symbol=Dem_SetEventStatus
        ResetEventStatus: can-be-invoked-concurrently=true, symbol=Dem_ResetEventStatus
        ResetEventDebounceStatus: can-be-invoked-concurrently=true, symbol=Dem_ResetEventDebounceStatus
        DcmClearDTC: can-be-invoked-concurrently=true, symbol=Dem_DcmClearDTC
        DcmGetNextFilteredDTCAndFDC: can-be-invoked-concurrently=true, symbol=Dem_DcmGetNextFilteredDTCAndFDC
        DcmEnableDTCSetting: can-be-invoked-concurrently=true, symbol=Dem_DcmEnableDTCSetting
        DcmGetFreezeFrameDataByDTC: can-be-invoked-concurrently=true, symbol=Dem_DcmGetFreezeFrameDataByDTC
        DcmGetExtendedDataRecordByDTC: can-be-invoked-concurrently=true, symbol=Dem_DcmGetExtendedDataRecordByDTC
        SetOperationCycleState: can-be-invoked-concurrently=true, symbol=Dem_SetOperationCycleState
  swc implementation DemImplementation: programming-language=C, behavior=DemInternalBehavior
